VERSION ""

NS_ :

BS_:

BU_: VCU BMU TMS Fire

BO_ 2550330351 V2BCMD: 8 VCU
 SG_ V2BCMDLifeSignal : 0|8@1+ (1,0) [0|255] ""  BMU
 SG_ V2BCMDHVOnOff : 8|2@1+ (1,0) [0|3] ""  BMU
 SG_ V2BCMDAux1OnOff : 10|2@1+ (1,0) [0|3] ""  BMU
 SG_ V2BCMDAux2OnOff : 12|2@1+ (1,0) [0|3] ""  BMU
 SG_ V2BCMDAux3OnOff : 14|2@1+ (1,0) [0|3] ""  BMU
 SG_ V2BCMDVehicleSpeed : 16|8@1+ (1,0) [0|255] "km/h"  BMU
 SG_ V2BCMDBatteryContactorPosST : 24|2@1+ (1,0) [0|3] ""  BMU
 SG_ V2BCMDBatteryContactorPosFlt : 26|2@1+ (1,0) [0|3] ""  BMU
 SG_ V2BCMDBatteryContactorNegST : 28|2@1+ (1,0) [0|3] ""  BMU
 SG_ V2BCMDBatteryContactorNegFlt : 30|2@1+ (1,0) [0|3] ""  BMU
 SG_ V2BCMDDCChargeContactorPosST : 32|2@1+ (1,0) [0|3] ""  BMU
 SG_ V2BCMDDCChargeContactorPosFlt : 34|2@1+ (1,0) [0|3] ""  BMU
 SG_ V2BCMDDCChargeContactorNegST : 36|2@1+ (1,0) [0|3] ""  BMU
 SG_ V2BCMDDCChargeContactorNegFlt : 38|2@1+ (1,0) [0|3] ""  BMU
 SG_ V2BCMDPantographContactorPosST : 40|2@1+ (1,0) [0|3] ""  BMU
 SG_ V2BCMDPantographContactorPosFlt : 42|2@1+ (1,0) [0|3] ""  BMU
 SG_ V2BCMDPantographContactorNegST : 44|2@1+ (1,0) [0|3] ""  BMU
 SG_ V2BCMDPantographContactorNegFlt : 46|2@1+ (1,0) [0|3] ""  BMU
 SG_ V2BCMDCharge1RelayST : 48|2@1+ (1,0) [0|3] ""  BMU
 SG_ V2BCMDCharge1RelayFlt : 50|2@1+ (1,0) [0|3] ""  BMU
 SG_ V2BCMDCharge2RelayST : 52|2@1+ (1,0) [0|3] ""  BMU
 SG_ V2BCMDCharge2RelayFlt : 54|2@1+ (1,0) [0|3] ""  BMU
 SG_ V2BCMDAux4RelayST : 56|2@1+ (1,0) [0|3] ""  BMU
 SG_ V2BCMDAux4RelayFlt : 58|2@1+ (1,0) [0|3] ""  BMU
 SG_ V2BCMDReserved1 : 60|2@1+ (1,0) [0|3] ""  BMU
 SG_ V2BCMDReserved2 : 62|2@1+ (1,0) [0|3] ""  BMU

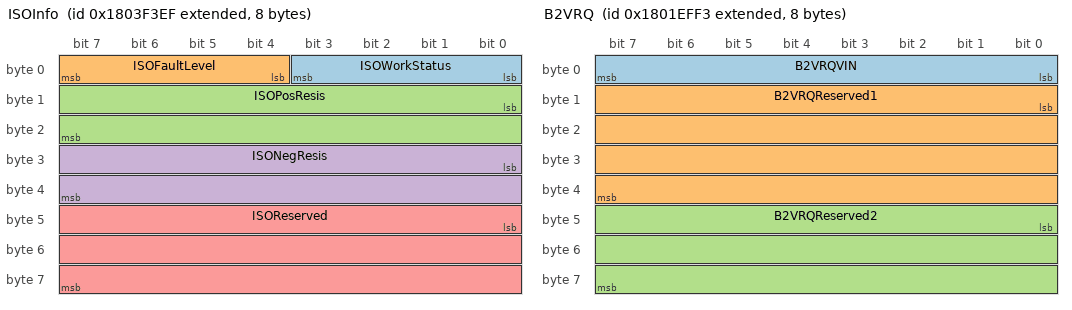
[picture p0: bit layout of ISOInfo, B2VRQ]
BO_ 2550395887 ISOInfo: 8 VCU
 SG_ ISOWorkStatus : 0|4@1+ (1,0) [0|15] ""  BMU
 SG_ ISOFaultLevel : 4|4@1+ (1,0) [0|15] ""  BMU
 SG_ ISOPosResis : 8|16@1+ (1,0) [0|60000] "kohm"  BMU
 SG_ ISONegResis : 24|16@1+ (1,0) [0|60000] "kohm"  BMU
 SG_ ISOReserved : 40|24@1+ (1,0) [0|16777215] ""  BMU

BO_ 2550263795 B2VRQ: 8 BMU
 SG_ B2VRQVIN : 0|8@1+ (1,0) [0|255] ""  VCU
 SG_ B2VRQReserved1 : 8|32@1+ (1,0) [0|4294967295] ""  VCU
 SG_ B2VRQReserved2 : 40|24@1+ (1,0) [0|16777215] ""  VCU

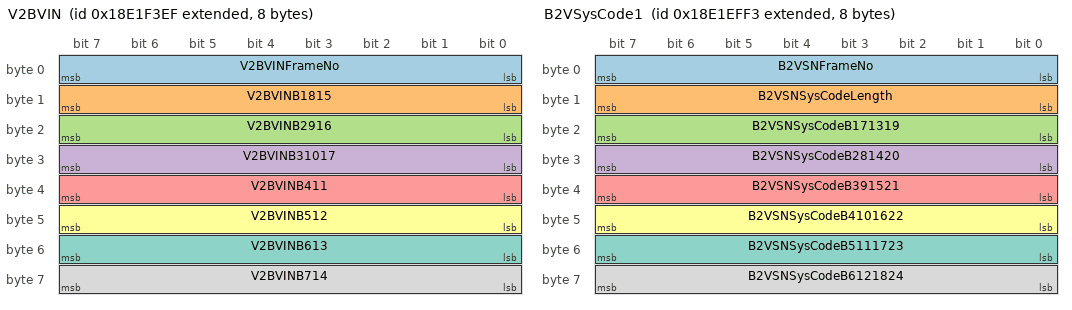
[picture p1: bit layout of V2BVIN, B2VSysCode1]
BO_ 2564944879 V2BVIN: 8 VCU
 SG_ V2BVINFrameNo : 0|8@1+ (1,0) [0|255] ""  BMU
 SG_ V2BVINB1815 : 8|8@1+ (1,0) [0|255] ""  BMU
 SG_ V2BVINB2916 : 16|8@1+ (1,0) [0|255] ""  BMU
 SG_ V2BVINB31017 : 24|8@1+ (1,0) [0|255] ""  BMU
 SG_ V2BVINB411 : 32|8@1+ (1,0) [0|255] ""  BMU
 SG_ V2BVINB512 : 40|8@1+ (1,0) [0|255] ""  BMU
 SG_ V2BVINB613 : 48|8@1+ (1,0) [0|255] ""  BMU
 SG_ V2BVINB714 : 56|8@1+ (1,0) [0|255] ""  BMU

BO_ 2564943859 B2VSysCode1: 8 BMU
 SG_ B2VSNFrameNo : 0|8@1+ (1,0) [0|255] ""  VCU
 SG_ B2VSNSysCodeLength : 8|8@1+ (1,0) [0|255] ""  VCU
 SG_ B2VSNSysCodeB171319 : 16|8@1+ (1,0) [0|255] ""  VCU
 SG_ B2VSNSysCodeB281420 : 24|8@1+ (1,0) [0|255] ""  VCU
 SG_ B2VSNSysCodeB391521 : 32|8@1+ (1,0) [0|255] ""  VCU
 SG_ B2VSNSysCodeB4101622 : 40|8@1+ (1,0) [0|255] ""  VCU
 SG_ B2VSNSysCodeB5111723 : 48|8@1+ (1,0) [0|255] ""  VCU
 SG_ B2VSNSysCodeB6121824 : 56|8@1+ (1,0) [0|255] ""  VCU

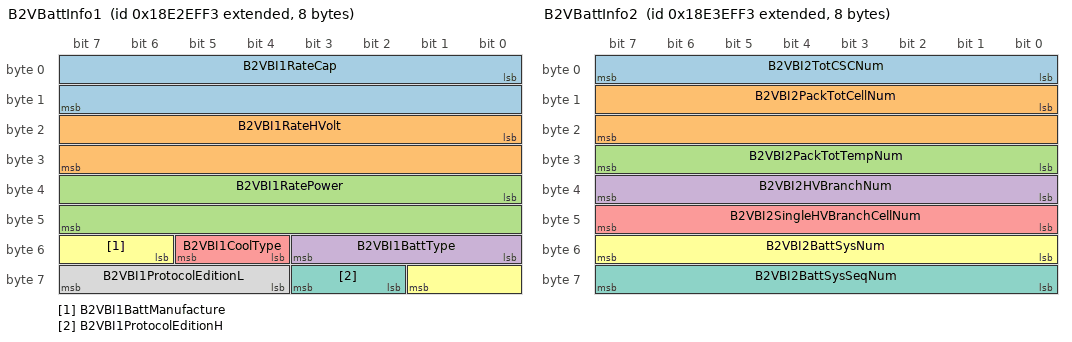
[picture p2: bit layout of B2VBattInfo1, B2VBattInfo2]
BO_ 2565009395 B2VBattInfo1: 8 BMU
 SG_ B2VBI1RateCap : 0|16@1+ (0.1,0) [0|6553.5] "Ah"  VCU
 SG_ B2VBI1RateHVolt : 16|16@1+ (0.1,0) [0|6553.5] "V"  VCU
 SG_ B2VBI1RatePower : 32|16@1+ (0.1,0) [0|6553.5] "kWh"  VCU
 SG_ B2VBI1BattType : 48|4@1+ (1,0) [0|15] ""  VCU
 SG_ B2VBI1CoolType : 52|2@1+ (1,0) [0|3] ""  VCU
 SG_ B2VBI1BattManufacture : 54|4@1+ (1,0) [0|15] ""  VCU
 SG_ B2VBI1ProtocolEditionH : 58|2@1+ (1,0) [0|3] ""  VCU
 SG_ B2VBI1ProtocolEditionL : 60|4@1+ (1,0) [0|15] ""  VCU

BO_ 2565074931 B2VBattInfo2: 8 BMU
 SG_ B2VBI2TotCSCNum : 0|8@1+ (1,0) [0|255] ""  VCU
 SG_ B2VBI2PackTotCellNum : 8|16@1+ (1,0) [0|65535] ""  VCU
 SG_ B2VBI2PackTotTempNum : 24|8@1+ (1,0) [0|255] ""  VCU
 SG_ B2VBI2HVBranchNum : 32|8@1+ (1,0) [0|5] ""  VCU
 SG_ B2VBI2SingleHVBranchCellNum : 40|8@1+ (1,0) [0|5] ""  VCU
 SG_ B2VBI2BattSysNum : 48|8@1+ (1,0) [0|5] ""  VCU
 SG_ B2VBI2BattSysSeqNum : 56|8@1+ (1,0) [0|5] ""  VCU

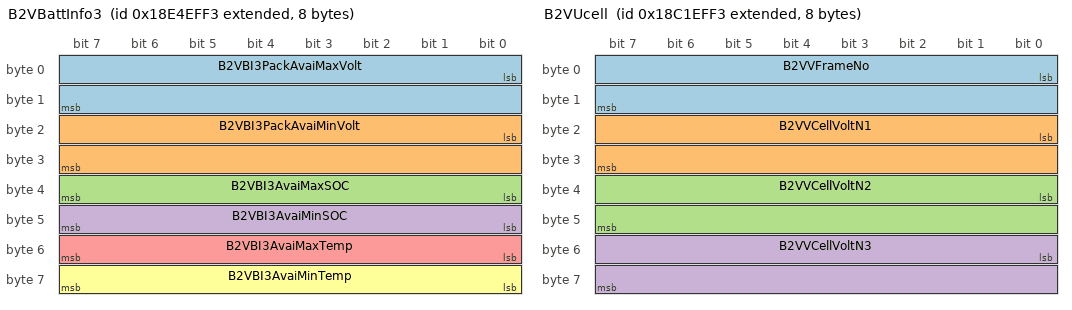
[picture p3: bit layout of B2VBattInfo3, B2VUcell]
BO_ 2565140467 B2VBattInfo3: 8 BMU
 SG_ B2VBI3PackAvaiMaxVolt : 0|16@1+ (0.1,0) [0|6553.5] "V"  VCU
 SG_ B2VBI3PackAvaiMinVolt : 16|16@1+ (0.1,0) [0|6553.5] "V"  VCU
 SG_ B2VBI3AvaiMaxSOC : 32|8@1+ (0.4,0) [0|102] "%"  VCU
 SG_ B2VBI3AvaiMinSOC : 40|8@1+ (0.4,0) [0|102] "%"  VCU
 SG_ B2VBI3AvaiMaxTemp : 48|8@1+ (1,-40) [-40|215] "℃"  VCU
 SG_ B2VBI3AvaiMinTemp : 56|8@1+ (1,-40) [-40|215] "℃"  VCU

BO_ 2562846707 B2VUcell: 8 BMU
 SG_ B2VVFrameNo : 0|16@1+ (1,0) [0|65535] ""  VCU
 SG_ B2VVCellVoltN1 : 16|16@1+ (0.001,0) [0|65.535] "V"  VCU
 SG_ B2VVCellVoltN2 : 32|16@1+ (0.001,0) [0|65.535] "V"  VCU
 SG_ B2VVCellVoltN3 : 48|16@1+ (0.001,0) [0|65.535] "V"  VCU

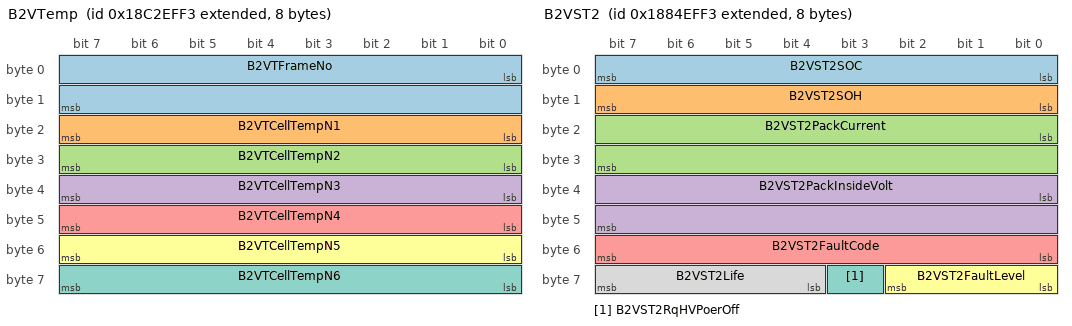
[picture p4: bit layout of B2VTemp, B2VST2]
BO_ 2562912243 B2VTemp: 8 BMU
 SG_ B2VTFrameNo : 0|16@1+ (1,0) [0|65535] ""  VCU
 SG_ B2VTCellTempN1 : 16|8@1+ (1,-40) [-40|215] "℃"  VCU
 SG_ B2VTCellTempN2 : 24|8@1+ (1,-40) [-40|215] "℃"  VCU
 SG_ B2VTCellTempN3 : 32|8@1+ (1,-40) [-40|215] "℃"  VCU
 SG_ B2VTCellTempN4 : 40|8@1+ (1,-40) [-40|215] "℃"  VCU
 SG_ B2VTCellTempN5 : 48|8@1+ (1,-40) [-40|215] "℃"  VCU
 SG_ B2VTCellTempN6 : 56|8@1+ (1,-40) [-40|215] "℃"  VCU

BO_ 2558652403 B2VFult132960: 8 BMU
 SG_ B2VFult132960Reserved1 : 0|2@1+ (1,0) [0|3] ""  VCU
 SG_ B2VFult1DelTemp : 2|2@1+ (1,0) [0|3] ""  VCU
 SG_ B2VFult1OverTemp : 4|2@1+ (1,0) [0|3] ""  VCU
 SG_ B2VFult1PackOverHVolt : 6|2@1+ (1,0) [0|3] ""  VCU
 SG_ B2VFult1PackLowHVolt : 8|2@1+ (1,0) [0|3] ""  VCU
 SG_ B2VFult1LowSOC : 10|2@1+ (1,0) [0|3] ""  VCU
 SG_ B2VFult1OverUcell : 12|2@1+ (1,0) [0|3] ""  VCU
 SG_ B2VFult1LowUcell : 14|2@1+ (1,0) [0|3] ""  VCU
 SG_ B2VFult1LowInsRes : 16|2@1+ (1,0) [0|3] ""  VCU
 SG_ B2VFult1UcellUniformity : 18|2@1+ (1,0) [0|3] ""  VCU
 SG_ B2VFult1OverChg : 20|2@1+ (1,0) [0|3] ""  VCU
 SG_ B2VFult1OverSOC : 22|2@1+ (1,0) [0|3] ""  VCU
 SG_ B2VFult1SOCChangeFast : 24|1@1+ (1,0) [0|1] ""  VCU
 SG_ B2VFult1BatSysNotMatch : 25|1@1+ (1,0) [0|1] ""  VCU
 SG_ B2VFult1HVILFault : 26|1@1+ (1,0) [0|1] ""  VCU
 SG_ B2VFult1FaultNum32960 : 27|5@1+ (1,0) [0|31] ""  VCU
 SG_ B2VFult132960Reserved2 : 32|32@1+ (1,0) [0|4294967295] ""  VCU

BO_ 2558717939 B2VFult2: 8 BMU
 SG_ B2VFult2FaultNum : 0|8@1+ (1,0) [0|255] ""  VCU
 SG_ B2VFult2CellOverDischrg : 8|1@1+ (1,0) [0|1] ""  VCU
 SG_ B2VFult2CellLowTemp : 9|1@1+ (1,0) [0|1] ""  VCU
 SG_ B2VFult2PackFireWarning : 10|1@1+ (1,0) [0|1] ""  VCU
 SG_ B2VFult2OverDischrgCurr : 11|2@1+ (1,0) [0|3] ""  VCU
 SG_ B2VFult2OverChrgCurrInTheDrive : 13|2@1+ (1,0) [0|3] ""  VCU
 SG_ B2VFult2CurrSensorErr : 15|1@1+ (1,0) [0|1] ""  VCU
 SG_ B2VFult2PowerSupplyErr : 16|1@1+ (1,0) [0|1] ""  VCU
 SG_ B2VFult2TMSErr : 17|1@1+ (1,0) [0|1] ""  VCU
 SG_ B2VFult2HeatungFilmErr : 18|1@1+ (1,0) [0|1] ""  VCU
 SG_ B2VFult2PackSelfProtect : 19|1@1+ (1,0) [0|1] ""  VCU
 SG_ B2VFult2MainLoopPrechrgErr : 20|1@1+ (1,0) [0|1] ""  VCU
 SG_ B2VFult2AuxLoopPrechrgErr : 21|1@1+ (1,0) [0|1] ""  VCU
 SG_ B2VFult2ChrgInsLowErr : 22|1@1+ (1,0) [0|1] ""  VCU
 SG_ B2VFult2ACANLost : 23|1@1+ (1,0) [0|1] ""  VCU
 SG_ B2VFult2InnerCommunicationErr : 24|1@1+ (1,0) [0|1] ""  VCU
 SG_ B2VFult2DCDCErr : 25|1@1+ (1,0) [0|1] ""  VCU
 SG_ B2VFult2BranchBreakErr : 26|1@1+ (1,0) [0|1] ""  VCU
 SG_ B2VFult2HeatRelayOpenErr : 27|1@1+ (1,0) [0|1] ""  VCU
 SG_ B2VFult2HeatRelayWeldErr : 28|1@1+ (1,0) [0|1] ""  VCU
 SG_ B2VFult2MainPosRelayOpenErr : 29|1@1+ (1,0) [0|1] ""  VCU
 SG_ B2VFult2MainPosRelayWeldErr : 30|1@1+ (1,0) [0|1] ""  VCU
 SG_ B2VFult2MainNegRelayOpenErr : 31|1@1+ (1,0) [0|1] ""  VCU
 SG_ B2VFult2MainNegRelayWeldErr : 32|1@1+ (1,0) [0|1] ""  VCU
 SG_ B2VFult2DCChrgPos1RelayOpenErr : 33|1@1+ (1,0) [0|1] ""  VCU
 SG_ B2VFult2DCChrgPos1RelayWeldErr : 34|1@1+ (1,0) [0|1] ""  VCU
 SG_ B2VFult2DCChrgNeg1RelayOpenErr : 35|1@1+ (1,0) [0|1] ""  VCU
 SG_ B2VFult2DCChrgNeg1RelayWeldErr : 36|1@1+ (1,0) [0|1] ""  VCU
 SG_ B2VFult2DCChrgPos2RelayOpenErr : 37|1@1+ (1,0) [0|1] ""  VCU
 SG_ B2VFult2DCChrgPos2RelayWeldErr : 38|1@1+ (1,0) [0|1] ""  VCU
 SG_ B2VFult2DCChrgNeg2RelayOpenErr : 39|1@1+ (1,0) [0|1] ""  VCU
 SG_ B2VFult2DCChrgNeg2RelayWeldErr : 40|1@1+ (1,0) [0|1] ""  VCU
 SG_ B2VFult2ACChrgPosRelayOpenErr : 41|1@1+ (1,0) [0|1] ""  VCU
 SG_ B2VFult2ACChrgPosRelayWeldErr : 42|1@1+ (1,0) [0|1] ""  VCU
 SG_ B2VFult2ACChrgNegRelayOpenErr : 43|1@1+ (1,0) [0|1] ""  VCU
 SG_ B2VFult2ACChrgNegRelayWeldErr : 44|1@1+ (1,0) [0|1] ""  VCU
 SG_ B2VFult2PantoChrgPosRelayOpenErr : 45|1@1+ (1,0) [0|1] ""  VCU
 SG_ B2VFult2PantoChrgPosRelayWeldErr : 46|1@1+ (1,0) [0|1] ""  VCU
 SG_ B2VFult2PantoChrgNegRelayOpenErr : 47|1@1+ (1,0) [0|1] ""  VCU
 SG_ B2VFult2PantoChrgNegRelayWeldErr : 48|1@1+ (1,0) [0|1] ""  VCU
 SG_ B2VFult2ChrgConnectErr : 49|1@1+ (1,0) [0|1] ""  VCU
 SG_ B2VFlt2OverDschrgCrrWhnInChrg : 50|1@1+ (1,0) [0|1] ""  VCU
 SG_ B2VFult2OverChrgCurrInTheChrg : 51|1@1+ (1,0) [0|1] ""  VCU
 SG_ B2VFult2ChrgNTCErr : 52|1@1+ (1,0) [0|1] ""  VCU
 SG_ B2VFult2ChrgNTCTempOver : 53|2@1+ (1,0) [0|3] ""  VCU
 SG_ B2VFult2ELockErr : 55|1@1+ (1,0) [0|1] ""  VCU
 SG_ B2VFult2FireDetectorErr : 56|1@1+ (1,0) [0|1] ""  VCU
 SG_ B2VFult2ContiChrgCurrOverLoad : 57|2@1+ (1,0) [0|3] ""  VCU
 SG_ B2VFult2SOCDifferErr : 59|1@1+ (1,0) [0|1] ""  VCU
 SG_ B2VFult2ContiDischrgCurrOverLoad : 60|2@1+ (1,0) [0|3] ""  VCU
 SG_ B2VFult2Reserved1 : 62|1@1+ (1,0) [0|1] ""  VCU
 SG_ B2VFult2Reserved2 : 63|1@1+ (1,0) [0|1] ""  VCU

BO_ 2558783475 B2VST1: 8 BMU
 SG_ B2VST1MainPosRelaySt : 0|2@1+ (1,0) [0|3] ""  VCU
 SG_ B2VST1MainNegRelaySt : 2|2@1+ (1,0) [0|3] ""  VCU
 SG_ B2VST1PrechrgRelaySt : 4|2@1+ (1,0) [0|3] ""  VCU
 SG_ B2VST1DCChrgPos1RelaySt : 6|2@1+ (1,0) [0|3] ""  VCU
 SG_ B2VST1DCChrgNeg1RelaySt : 8|2@1+ (1,0) [0|3] ""  VCU
 SG_ B2VST1DCChrgPos2RelaySt : 10|2@1+ (1,0) [0|3] ""  VCU
 SG_ B2VST1DCChrgNeg2RelaySt : 12|2@1+ (1,0) [0|3] ""  VCU
 SG_ B2VST1HeatPosRelaySt : 14|2@1+ (1,0) [0|3] ""  VCU
 SG_ B2VST1HeatNegRelaySt : 16|2@1+ (1,0) [0|3] ""  VCU
 SG_ B2VST1PantoChrgPosRelaySt : 18|2@1+ (1,0) [0|3] ""  VCU
 SG_ B2VST1PantoChrgNegRelaySt : 20|2@1+ (1,0) [0|3] ""  VCU
 SG_ B2VST1ACChrgPosRelaySt : 22|2@1+ (1,0) [0|3] ""  VCU
 SG_ B2VST1ACChrgNegRelaySt : 24|2@1+ (1,0) [0|3] ""  VCU
 SG_ B2VST1Aux1RelaySt : 26|2@1+ (1,0) [0|3] ""  VCU
 SG_ B2VST1Aux2RelaySt : 28|2@1+ (1,0) [0|3] ""  VCU
 SG_ B2VST1Aux3RelaySt : 30|2@1+ (1,0) [0|3] ""  VCU
 SG_ B2VST1BMSHVStatus : 32|2@1+ (1,0) [0|3] ""  VCU
 SG_ B2VST1BMSBalanceStatus : 34|1@1+ (1,0) [0|1] ""  VCU
 SG_ B2VST1DCChrgConnectSt : 35|2@1+ (1,0) [0|3] ""  VCU
 SG_ B2VST1PantoChrgConnectSt : 37|1@1+ (1,0) [0|1] ""  VCU
 SG_ B2VST1ACChrgConnectSt : 38|1@1+ (1,0) [0|1] ""  VCU
 SG_ B2VST1ChrgMode : 39|2@1+ (1,0) [0|3] ""  VCU
 SG_ B2VST1ChrgStatus : 41|2@1+ (1,0) [0|3] ""  VCU
 SG_ B2VST1HeatingStatus : 43|1@1+ (1,0) [0|1] ""  VCU
 SG_ B2VST1CoolingStatus : 44|2@1+ (1,0) [0|3] ""  VCU
 SG_ B2VST1RechrgCycels : 46|18@1+ (1,0) [0|262143] ""  VCU

BO_ 2558849011 B2VST2: 8 BMU
 SG_ B2VST2SOC : 0|8@1+ (0.4,0) [0|100] "%"  VCU
 SG_ B2VST2SOH : 8|8@1+ (0.4,0) [0|100] "%"  VCU
 SG_ B2VST2PackCurrent : 16|16@1+ (0.1,-1000) [-1000|1000] "A"  VCU
 SG_ B2VST2PackInsideVolt : 32|16@1+ (0.1,0) [0|65535] "V"  VCU
 SG_ B2VST2FaultCode : 48|8@1+ (1,0) [0|255] ""  VCU
 SG_ B2VST2FaultLevel : 56|3@1+ (1,0) [0|7] ""  VCU
 SG_ B2VST2RqHVPoerOff : 59|1@1+ (1,0) [0|1] ""  VCU
 SG_ B2VST2Life : 60|4@1+ (1,0) [0|15] ""  VCU

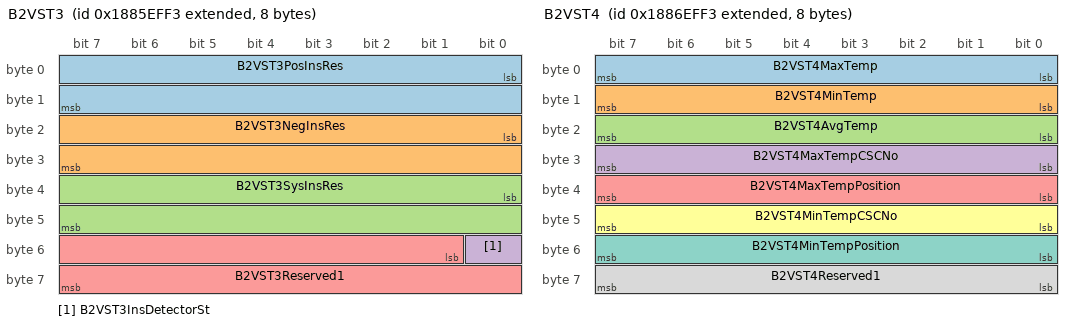
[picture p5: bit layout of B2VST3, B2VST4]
BO_ 2558914547 B2VST3: 8 BMU
 SG_ B2VST3PosInsRes : 0|16@1+ (1,0) [0|60000] "kohm"  VCU
 SG_ B2VST3NegInsRes : 16|16@1+ (1,0) [0|60000] "kohm"  VCU
 SG_ B2VST3SysInsRes : 32|16@1+ (1,0) [0|60000] "kohm"  VCU
 SG_ B2VST3InsDetectorSt : 48|1@1+ (1,0) [0|1] ""  VCU
 SG_ B2VST3Reserved1 : 49|15@1+ (1,0) [0|32767] ""  VCU

BO_ 2558980083 B2VST4: 8 BMU
 SG_ B2VST4MaxTemp : 0|8@1+ (1,-40) [-40|215] "℃"  VCU
 SG_ B2VST4MinTemp : 8|8@1+ (1,-40) [-40|215] "℃"  VCU
 SG_ B2VST4AvgTemp : 16|8@1+ (1,-40) [-40|215] "℃"  VCU
 SG_ B2VST4MaxTempCSCNo : 24|8@1+ (1,0) [1|255] ""  VCU
 SG_ B2VST4MaxTempPosition : 32|8@1+ (1,0) [1|255] ""  VCU
 SG_ B2VST4MinTempCSCNo : 40|8@1+ (1,0) [1|255] ""  VCU
 SG_ B2VST4MinTempPosition : 48|8@1+ (1,0) [1|255] ""  VCU
 SG_ B2VST4Reserved1 : 56|8@1+ (1,0) [1|255] ""  VCU

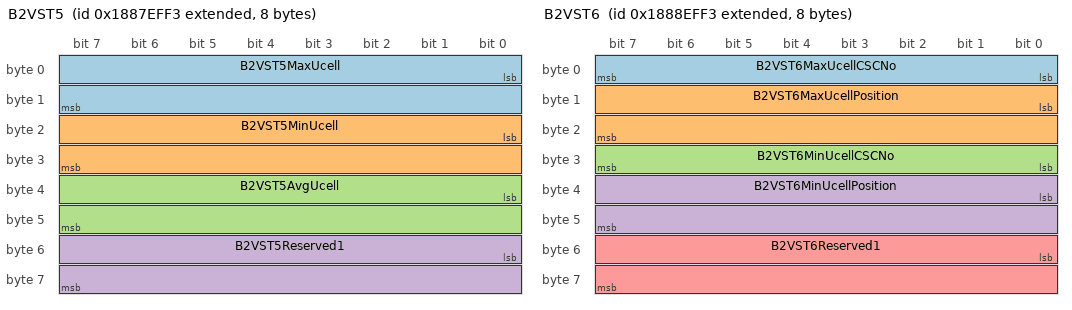
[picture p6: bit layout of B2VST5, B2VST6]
BO_ 2559045619 B2VST5: 8 BMU
 SG_ B2VST5MaxUcell : 0|16@1+ (0.001,0) [0|65.535] "V"  VCU
 SG_ B2VST5MinUcell : 16|16@1+ (0.001,0) [0|65.535] "V"  VCU
 SG_ B2VST5AvgUcell : 32|16@1+ (0.001,0) [0|65.535] "V"  VCU
 SG_ B2VST5Reserved1 : 48|16@1+ (1,0) [0|65535] ""  VCU

BO_ 2559111155 B2VST6: 8 BMU
 SG_ B2VST6MaxUcellCSCNo : 0|8@1+ (1,0) [0|255] ""  VCU
 SG_ B2VST6MaxUcellPosition : 8|16@1+ (1,0) [0|65535] ""  VCU
 SG_ B2VST6MinUcellCSCNo : 24|8@1+ (1,0) [0|255] ""  VCU
 SG_ B2VST6MinUcellPosition : 32|16@1+ (1,0) [0|65535] ""  VCU
 SG_ B2VST6Reserved1 : 48|16@1+ (1,0) [0|65535] ""  VCU

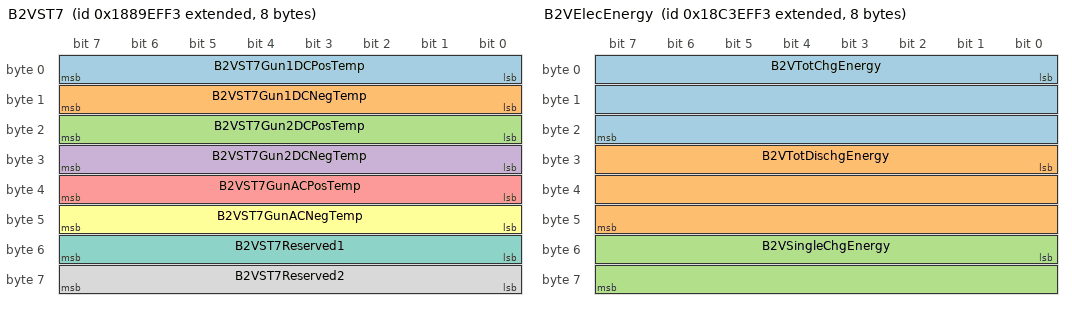
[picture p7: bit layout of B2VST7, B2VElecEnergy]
BO_ 2559176691 B2VST7: 8 BMU
 SG_ B2VST7Gun1DCPosTemp : 0|8@1+ (1,-40) [-40|215] "℃"  VCU
 SG_ B2VST7Gun1DCNegTemp : 8|8@1+ (1,-40) [-40|215] "℃"  VCU
 SG_ B2VST7Gun2DCPosTemp : 16|8@1+ (1,-40) [-40|215] "℃"  VCU
 SG_ B2VST7Gun2DCNegTemp : 24|8@1+ (1,-40) [-40|215] "℃"  VCU
 SG_ B2VST7GunACPosTemp : 32|8@1+ (1,-40) [-40|215] "℃"  VCU
 SG_ B2VST7GunACNegTemp : 40|8@1+ (1,-40) [-40|215] "℃"  VCU
 SG_ B2VST7Reserved1 : 48|8@1+ (1,0) [0|255] ""  VCU
 SG_ B2VST7Reserved2 : 56|8@1+ (1,0) [0|255] ""  VCU

BO_ 2562977779 B2VElecEnergy: 8 BMU
 SG_ B2VTotChgEnergy : 0|24@1+ (1,0) [0|16777215] "kwh"  VCU
 SG_ B2VTotDischgEnergy : 24|24@1+ (1,0) [0|16777215] "kwh"  VCU
 SG_ B2VSingleChgEnergy : 48|16@1+ (0.1,0) [0|6553.5] "kwh"  VCU

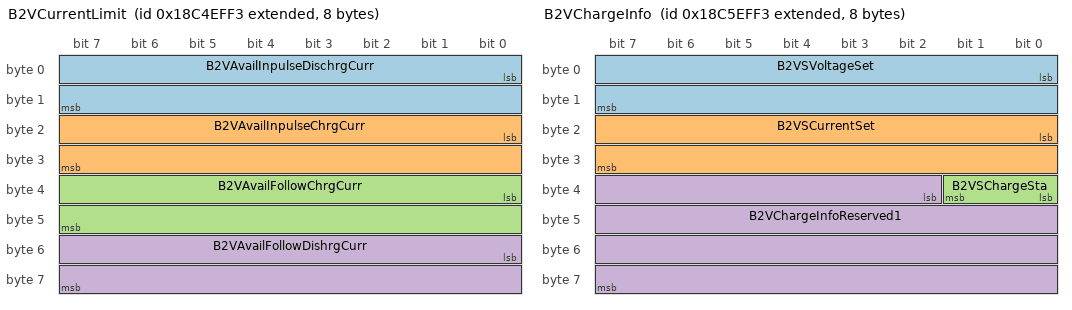
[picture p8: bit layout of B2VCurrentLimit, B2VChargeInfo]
BO_ 2563043315 B2VCurrentLimit: 8 BMU
 SG_ B2VAvailInpulseDischrgCurr : 0|16@1+ (0.1,0) [0|6553.5] "A"  VCU
 SG_ B2VAvailInpulseChrgCurr : 16|16@1+ (0.1,0) [0|6553.5] "A"  VCU
 SG_ B2VAvailFollowChrgCurr : 32|16@1+ (0.1,0) [0|6553.5] "A"  VCU
 SG_ B2VAvailFollowDishrgCurr : 48|16@1+ (0.1,0) [0|6553.5] "A"  VCU

BO_ 2563108851 B2VChargeInfo: 8 BMU
 SG_ B2VSVoltageSet : 0|16@1+ (0.1,0) [0|6553.5] "V"  VCU
 SG_ B2VSCurrentSet : 16|16@1+ (0.1,0) [0|6553.5] "A"  VCU
 SG_ B2VSChargeSta : 32|2@1+ (1,0) [0|3] ""  VCU
 SG_ B2VChargeInfoReserved1 : 34|30@1+ (1,0) [0|1073741823] ""  VCU

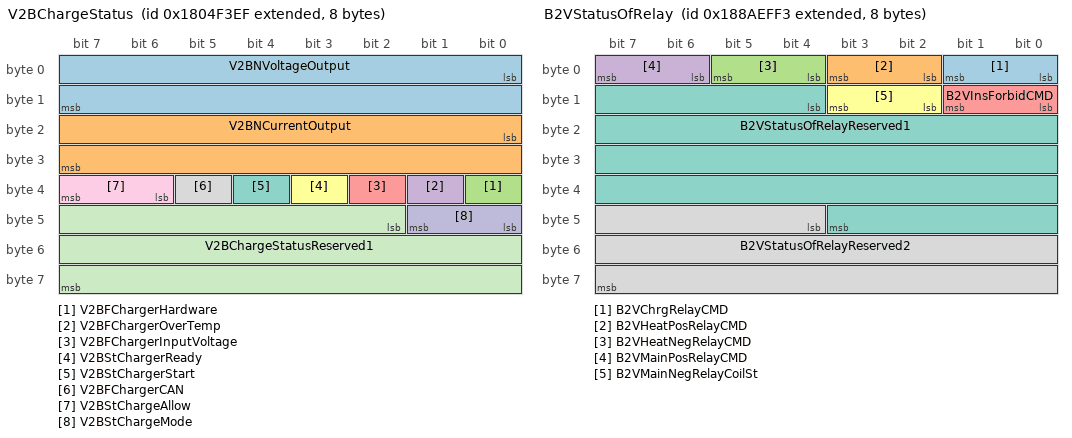
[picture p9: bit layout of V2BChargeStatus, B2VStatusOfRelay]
BO_ 2550461423 V2BChargeStatus: 8 VCU
 SG_ V2BNVoltageOutput : 0|16@1+ (0.1,0) [0|6553.5] "V"  BMU
 SG_ V2BNCurrentOutput : 16|16@1+ (0.1,0) [0|6553.5] "A"  BMU
 SG_ V2BFChargerHardware : 32|1@1+ (1,0) [0|1] ""  BMU
 SG_ V2BFChargerOverTemp : 33|1@1+ (1,0) [0|1] ""  BMU
 SG_ V2BFChargerInputVoltage : 34|1@1+ (1,0) [0|1] ""  BMU
 SG_ V2BStChargerReady : 35|1@1+ (1,0) [0|1] ""  BMU
 SG_ V2BStChargerStart : 36|1@1+ (1,0) [0|1] ""  BMU
 SG_ V2BFChargerCAN : 37|1@1+ (1,0) [0|1] ""  BMU
 SG_ V2BStChargeAllow : 38|2@1+ (1,0) [0|3] ""  BMU
 SG_ V2BStChargeMode : 40|2@1+ (1,0) [0|3] ""  BMU
 SG_ V2BChargeStatusReserved1 : 42|22@1+ (1,0) [0|8388607] ""  BMU

BO_ 2559242227 B2VStatusOfRelay: 8 BMU
 SG_ B2VChrgRelayCMD : 0|2@1+ (1,0) [0|3] ""  VCU
 SG_ B2VHeatPosRelayCMD : 2|2@1+ (1,0) [0|3] ""  VCU
 SG_ B2VHeatNegRelayCMD : 4|2@1+ (1,0) [0|3] ""  VCU
 SG_ B2VMainPosRelayCMD : 6|2@1+ (1,0) [0|3] ""  VCU
 SG_ B2VInsForbidCMD : 8|2@1+ (1,0) [0|3] ""  VCU
 SG_ B2VMainNegRelayCoilSt : 10|2@1+ (1,0) [0|3] ""  VCU
 SG_ B2VStatusOfRelayReserved1 : 12|32@1+ (1,0) [0|4294967295] ""  VCU
 SG_ B2VStatusOfRelayReserved2 : 44|20@1+ (1,0) [0|1048575] ""  VCU

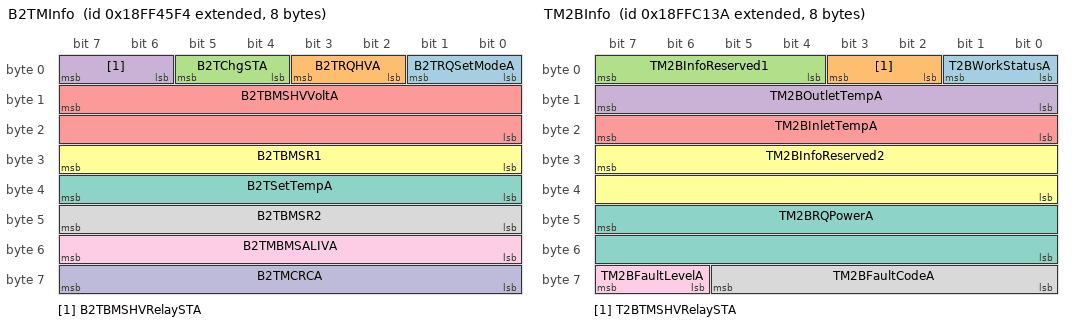
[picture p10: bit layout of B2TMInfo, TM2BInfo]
BO_ 2566866420 B2TMInfo: 8 BMU
 SG_ B2TRQSetModeA : 1|2@0+ (1,0) [0|3] ""  TMS
 SG_ B2TRQHVA : 3|2@0+ (1,0) [0|3] ""  TMS
 SG_ B2TChgSTA : 5|2@0+ (1,0) [0|3] ""  TMS
 SG_ B2TBMSHVRelaySTA : 7|2@0+ (1,0) [0|3] ""  TMS
 SG_ B2TBMSHVVoltA : 15|16@0+ (1,0) [0|65535] ""  TMS
 SG_ B2TBMSR1 : 31|8@0+ (1,0) [0|255] ""  TMS
 SG_ B2TSetTempA : 39|8@0+ (1,-40) [-40|215] "℃"  TMS
 SG_ B2TBMSR2 : 47|8@0+ (1,0) [0|255] ""  TMS
 SG_ B2TMBMSALIVA : 55|8@0+ (1,0) [0|255] ""  TMS
 SG_ B2TMCRCA : 63|8@0+ (1,0) [0|255] ""  TMS

BO_ 2566897978 TM2BInfo: 8 TMS
 SG_ T2BWorkStatusA : 1|2@0+ (1,0) [0|3] ""  BMU
 SG_ T2BTMSHVRelaySTA : 3|2@0+ (1,0) [0|3] ""  BMU
 SG_ TM2BInfoReserved1 : 7|4@0+ (1,0) [0|15] ""  BMU
 SG_ TM2BOutletTempA : 15|8@0+ (1,-40) [-40|215] "℃"  BMU
 SG_ TM2BInletTempA : 23|8@0+ (1,-40) [-40|215] "℃"  BMU
 SG_ TM2BInfoReserved2 : 31|16@0+ (1,0) [0|65535] ""  BMU
 SG_ TM2BRQPowerA : 47|16@0+ (0.1,0) [0|6553.5] "Kw"  BMU
 SG_ TM2BFaultCodeA : 61|6@0+ (1,0) [0|63] ""  BMU
 SG_ TM2BFaultLevelA : 63|2@0+ (1,0) [0|3] ""  BMU

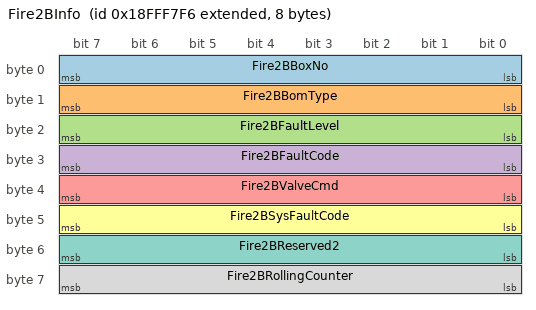
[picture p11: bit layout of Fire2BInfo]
BO_ 2566911990 Fire2BInfo: 8 Fire
 SG_ Fire2BBoxNo : 0|8@1+ (1,0) [0|255] ""  BMU
 SG_ Fire2BBomType : 8|8@1+ (1,0) [0|255] ""  BMU
 SG_ Fire2BFaultLevel : 16|8@1+ (1,0) [0|255] ""  BMU
 SG_ Fire2BFaultCode : 24|8@1+ (1,0) [0|255] ""  BMU
 SG_ Fire2BValveCmd : 32|8@1+ (1,0) [0|255] ""  BMU
 SG_ Fire2BSysFaultCode : 40|8@1+ (1,0) [0|255] ""  BMU
 SG_ Fire2BReserved2 : 48|8@1+ (1,0) [0|255] ""  BMU
 SG_ Fire2BRollingCounter : 56|8@1+ (1,0) [0|255] ""  BMU

CM_ BO_ 2550330351 "VCU发送到BMS的命令
The command message from VCU to BMS";
CM_ SG_ 2550330351 V2BCMDLifeSignal "VCU生命信号
Life signal of VCU";
CM_ SG_ 2550330351 V2BCMDHVOnOff "整车发给BMS的主回路上下高压指令
High voltage power on/off command from VCU to BMS";
CM_ SG_ 2550330351 V2BCMDAux1OnOff "整车发给BMS的附件1回路上下高压指令（无该附件回路则发0x00）
Command of high voltage to auxiliary_1 contactor(filled in 0 if BMS have no auxiliary_1 contactor)";
CM_ SG_ 2550330351 V2BCMDAux2OnOff "整车发给BMS的附件2回路上下高压指令（无该附件回路则发0x00）
Command of high voltage to auxiliary_2 contactor(filled in 0 if BMS have no auxiliary_2 contactor)";
CM_ SG_ 2550330351 V2BCMDAux3OnOff "整车发给BMS的附件3回路上下高压指令（无该附件回路则发0x00）
Command of high voltage to auxiliary_3 contactor
(filled in 0 if BMS have no auxiliary_3 contactor)";
CM_ SG_ 2550330351 V2BCMDVehicleSpeed "车速
Vehicle Speed";
CM_ SG_ 2550330351 V2BCMDBatteryContactorPosST "整车端电池正继电器触点状态（无该继电器则发0x00）
Status of vehicle Battery Contactor-positive (filled in 0 if vehicle have no this contactor)";
CM_ SG_ 2550330351 V2BCMDBatteryContactorPosFlt "整车端电池正继电器故障状态（无该继电器则发0x00）
Fault of vehicle Battery Contactor-positive  (filled in 0 if vehicle have no this contactor)";
CM_ SG_ 2550330351 V2BCMDBatteryContactorNegST "整车端电池负继电器触点状态（无该继电器则发0x00）
Status of vehicle Battery Contactor-negative (filled in 0 if vehicle have no vehicle Battery Contactor-negative)";
CM_ SG_ 2550330351 V2BCMDBatteryContactorNegFlt "整车端电池负继电器故障状态（无该继电器则发0x00）
Fault of vehicle Battery Contactor-negative (filled in 0 if vehicle have no vehicle Battery Contactor-negative)";
CM_ SG_ 2550330351 V2BCMDDCChargeContactorPosST "整车端DC Charge Contactor正触点状态（无该继电器则发0x00）
Status of vehicle DC Charge Contactor positive (filled in 0 if vehicle have no this contactor)";
CM_ SG_ 2550330351 V2BCMDDCChargeContactorPosFlt "整车端DC Charge Contactor正故障状态（无该继电器则发0x00）
Fault of vehicle DC Charge Contactor positive (filled in 0 if vehicle have no this contactor)";
CM_ SG_ 2550330351 V2BCMDDCChargeContactorNegST "整车端DC Charge Contactor负触点状态（无该继电器则发0x00）
Status of vehicle DC Charge Contactor negative (filled in 0 if vehicle have no this contactor)";
CM_ SG_ 2550330351 V2BCMDDCChargeContactorNegFlt "整车端DC Charge Contactor负故障状态（无该继电器则发0x00）
Fault of vehicle DC Charge Contactor negative (filled in 0 if vehicle have no this contactor)";
CM_ SG_ 2550330351 V2BCMDPantographContactorPosST "整车端Pantograph Contactor正触点状态（无该继电器则发0x00）
Status of vehicle Pantograph Contactor positive (filled in 0 if vehicle have no this contactor)";
CM_ SG_ 2550330351 V2BCMDPantographContactorPosFlt "整车端Pantograph Contactor正故障状态（无该继电器则发0x00）
Fault of vehicle Pantograph Contactor positive (filled in 0 if vehicle have no this contactor)";
CM_ SG_ 2550330351 V2BCMDPantographContactorNegST "整车端Pantograph Contactor负触点状态（无该继电器则发0x00）
Status of vehicle Pantograph Contactor negative (filled in 0 if vehicle have no this contactor)";
CM_ SG_ 2550330351 V2BCMDPantographContactorNegFlt "整车端Pantograph Contactor负故障状态（无该继电器则发0x00）
Fault of vehicle Pantograph Contactor negative (filled in 0 if vehicle have no this contactor)";
CM_ SG_ 2550330351 V2BCMDCharge1RelayST "整车端Charge1 Contactor正触点状态（无该继电器则发0x00）
Status of vehicle Charge1 Contactor positive (filled in 0 if vehicle have no this contactor)";
CM_ SG_ 2550330351 V2BCMDCharge1RelayFlt "整车端Charge1 Contactor正故障状态（无该继电器则发0x00）
Fault of vehicle Charge1 Contactor positive (filled in 0 if vehicle have no this contactor)";
CM_ SG_ 2550330351 V2BCMDCharge2RelayST "整车端Charge2 Contactor正触点状态（无该继电器则发0x00）
Status of vehicle Charge2 Contactor positive (filled in 0 if vehicle have no this contactor)";
CM_ SG_ 2550330351 V2BCMDCharge2RelayFlt "整车端Charge2 Contactor正故障状态（无该继电器则发0x00）
Fault of vehicle Charge2 Contactor positive (filled in 0 if vehicle have no this contactor)";
CM_ SG_ 2550330351 V2BCMDAux4RelayST "整车端辅件4接触器触点状态（无该继电器则发0x00）
Status of vehicle auxiliary_4 contactor(filled in 0 if vehicle have no auxiliary_4 contactor)";
CM_ SG_ 2550330351 V2BCMDAux4RelayFlt "整车端辅件4接触器故障状态（无该继电器则发0x00）
Fault of vehicle auxiliary_4 contactor(filled in 0 if vehicle have no auxiliary_4 contactor)";
CM_ SG_ 2550330351 V2BCMDReserved1 "预留1(填充0)
Reserved-1(filled in 0)";
CM_ SG_ 2550330351 V2BCMDReserved2 "预留2(填充0)
Reserved-2(filled in 0)";
CM_ BO_ 2550395887 "整车采集的绝缘值（多合一项目或者整车采绝缘的项目）
vehicle insulation information(Project that vehicle have insulation montoring )";
CM_ SG_ 2550395887 ISOWorkStatus "绝缘检测仪工作状态（多合一项目或者整车采绝缘的项目）
Insulation detection status(Project that vehicle have insulation montoring )";
CM_ SG_ 2550395887 ISOFaultLevel "绝缘故障等级（多合一项目或者整车采绝缘的项目）
Fault level of insulation detection(Project that vehicle have insulation montoring )";
CM_ SG_ 2550395887 ISOPosResis "正极绝缘值（多合一项目或者整车采绝缘的项目）
Positive insulation value(Project that vehicle have insulation montoring )";
CM_ SG_ 2550395887 ISONegResis "负极绝缘值（多合一项目或者整车采绝缘的项目）
Negative insulation value(Project that vehicle have insulation montoring )";
CM_ SG_ 2550395887 ISOReserved "Reserved(填充0)
Reserved(filled in 0)";
CM_ BO_ 2550263795 "BMU发送的VIN码请求
The VIN requirement message from BMU to VCU";
CM_ SG_ 2550263795 B2VRQVIN "BMS请求VIN码标志
VIN requirement flag";
CM_ SG_ 2550263795 B2VRQReserved1 "预留(填充0)
Reserved(filled in 0)";
CM_ SG_ 2550263795 B2VRQReserved2 "预留(填充0)
Reserved(filled in 0)";
CM_ BO_ 2564944879 "VCU发送到BMS的VIN(响应B2V_RQVIN，请求1次，响应3帧--3帧发送一次完整的VIN)
The VIN information from VCU to BMS(respond to the message B2V_RQVIN ）";
CM_ SG_ 2564944879 V2BVINFrameNo "VIN帧序号
Serial number of frame VIN";
CM_ SG_ 2564944879 V2BVINB1815 "车辆VIN码1，8，15字符(ASCII码)
Vehicle VIN 1,8,15 character（ASCII）";
CM_ SG_ 2564944879 V2BVINB2916 "车辆VIN码2，9，16字符(ASCII码)
Vehicle VIN 1,8,15 character（ASCII）";
CM_ SG_ 2564944879 V2BVINB31017 "车辆VIN码3，10，17字符(ASCII码)
Vehicle VIN 3,10,17character（ASCII）";
CM_ SG_ 2564944879 V2BVINB411 "车辆VIN码4，11字符(ASCII码)
Vehicle VIN 4,11character（ASCII）";
CM_ SG_ 2564944879 V2BVINB512 "车辆VIN码5，12字符(ASCII码)
Vehicle VIN 5,12character（ASCII）";
CM_ SG_ 2564944879 V2BVINB613 "车辆VIN码6，13字符(ASCII码)
Vehicle VIN 6,13character（ASCII）";
CM_ SG_ 2564944879 V2BVINB714 "车辆VIN码7，14字符(ASCII码)
Vehicle VIN 7,14character（ASCII）";
CM_ BO_ 2564943859 "BMS发送到车载终端的编码信息
The system code Information  from BMS to the vehicle terminal";
CM_ SG_ 2564943859 B2VSNFrameNo "电池编码信息帧序号
Battery Code number of frame VIN";
CM_ SG_ 2564943859 B2VSNSysCodeLength "电池编码长度
Length of battery code";
CM_ SG_ 2564943859 B2VSNSysCodeB171319 "电池编码(SN)字符1,7,13,19(ASCII)
Battery Code(SN) Character 1,7,13,19(ASCII)";
CM_ SG_ 2564943859 B2VSNSysCodeB281420 "电池编码(SN)字符2,8,14,20(ASCII)
Battery Code(SN) Character 2,8,14,20(ASCII)";
CM_ SG_ 2564943859 B2VSNSysCodeB391521 "电池编码(SN)字符3,9,15,21(ASCII)
Battery Code(SN) Character 3,9,15,21(ASCII)";
CM_ SG_ 2564943859 B2VSNSysCodeB4101622 "电池编码(SN)字符4,10,16,22(ASCII)
Battery Code(SN) Character4,10,16,22(ASCII)";
CM_ SG_ 2564943859 B2VSNSysCodeB5111723 "电池编码(SN)字符5,11,17,23(ASCII)
Battery Code(SN) Character 5,11,17,23(ASCII)";
CM_ SG_ 2564943859 B2VSNSysCodeB6121824 "电池编码(SN)字符6,12,18,24(ASCII)
Battery Code(SN) Character 6,12,18,24(ASCII)";
CM_ BO_ 2565009395 "电池包基本信息1
The Basic Battery Information-1 from BMS to VCU";
CM_ SG_ 2565009395 B2VBI1RateCap "电池包额定容量
Rated Capacity of Battery";
CM_ SG_ 2565009395 B2VBI1RateHVolt "电池包额定电压
Rated Voltage of Battery";
CM_ SG_ 2565009395 B2VBI1RatePower "电池包额定总能量
Rated total energy of Battery";
CM_ SG_ 2565009395 B2VBI1BattType "电池类型
Type of battery";
CM_ SG_ 2565009395 B2VBI1CoolType "电池冷却方式
Type of Battery Cooling mode";
CM_ SG_ 2565009395 B2VBI1BattManufacture "电池厂家
Battery manufacutre";
CM_ SG_ 2565009395 B2VBI1ProtocolEditionH "通讯协议版本高位（例：版本为3.1，则此处发3）
Porotocol Edition-high";
CM_ SG_ 2565009395 B2VBI1ProtocolEditionL "通讯协议版本低位（例：版本为3.1，则此处发1）
Porotocol Edition-low";
CM_ BO_ 2565074931 "电池包基本信息2
The Basic Battery Information-2 from BMS to VCU";
CM_ SG_ 2565074931 B2VBI2TotCSCNum "电池系统中CSC总的数目(电池监控单元数目)
Sum of CSC";
CM_ SG_ 2565074931 B2VBI2PackTotCellNum "PACK中单体电芯的总数目
Sum of cell in pack";
CM_ SG_ 2565074931 B2VBI2PackTotTempNum "PACK中电芯温度点(探针)的总数目
Sum of Temperature Probe in PACK";
CM_ SG_ 2565074931 B2VBI2HVBranchNum "电池系统高压支路数
High-voltage Branch of battery";
CM_ SG_ 2565074931 B2VBI2SingleHVBranchCellNum "电池系统单支路电芯数
Sum of cell in single branch";
CM_ SG_ 2565074931 B2VBI2BattSysNum "可充电储能系统数目（EV默认1，满足GB32960要求）
Sum of energy storage system(GBT 32960)";
CM_ SG_ 2565074931 B2VBI2BattSysSeqNum "可充电储能系统序号（EV默认1，满足GB32960要求）
Serial number of energy storage system(GBT 32960)";
CM_ BO_ 2565140467 "电池包基本信息3
The Basic Battery Information-3 from BMS to VCU";
CM_ SG_ 2565140467 B2VBI3PackAvaiMaxVolt "PACK可用电压上限(根据技术协议)
Maximum available voltage of battery pack";
CM_ SG_ 2565140467 B2VBI3PackAvaiMinVolt "PACK可用电压下限(根据技术协议)
Minimum available voltage of battery pack";
CM_ SG_ 2565140467 B2VBI3AvaiMaxSOC "PACK可用最高SOC(根据技术协议)
Maximum available SOC of battery pack";
CM_ SG_ 2565140467 B2VBI3AvaiMinSOC "PACK可用最低SOC(根据技术协议)
Minimum availableSOC of battery pack";
CM_ SG_ 2565140467 B2VBI3AvaiMaxTemp "PACK可用温度上限(根据技术协议)
Maximum available temperature of battery pack";
CM_ SG_ 2565140467 B2VBI3AvaiMinTemp "PACK可用温度下限(根据技术协议)
Minimum available temperature of battery pack";
CM_ BO_ 2562846707 "BMS的单体详细电压
The cell voltage information of BMS";
CM_ SG_ 2562846707 B2VVFrameNo "本帧起始单体电压序号（从1开始）
Cell serial number of this Frame(Started from 1)";
CM_ SG_ 2562846707 B2VVCellVoltN1 "本帧第1号电池电压（最后一帧发不满，则发送0xFFFF）
Voltage of No.1 cell  in this frame (Send 0xFFFF if the voltage value is invail)";
CM_ SG_ 2562846707 B2VVCellVoltN2 "本帧第2号电池电压（最后一帧发不满，则发送0xFFFF）
Voltage of No.2 cell  in this frame (Send 0xFFFF if the voltage value is invail)";
CM_ SG_ 2562846707 B2VVCellVoltN3 "本帧第3号电池电压（最后一帧发不满，则发送0xFFFF）
Voltage of No.3 cell  in this frame (Send 0xFFFF if the voltage value is invail)";
CM_ BO_ 2562912243 "BMS的电芯详细温度
The cell temperature information of BMS";
CM_ SG_ 2562912243 B2VTFrameNo "本帧起始单体温度序号（从1开始）
Temperature probe serial number of this Frame(Started from 1)";
CM_ SG_ 2562912243 B2VTCellTempN1 "本帧第1号电池温度（最后一帧发不满，则发送0xFF）
Temperature of No.1 probe  in this frame (Send 0xFF if the temperature value is invail)";
CM_ SG_ 2562912243 B2VTCellTempN2 "本帧第2号电池温度（最后一帧发不满，则发送0xFF）
Temperature of No.2 probe  in this frame (Send 0xFF if the temperature value is invail)";
CM_ SG_ 2562912243 B2VTCellTempN3 "本帧第3号电池温度（最后一帧发不满，则发送0xFF）
Temperature of No.3 probe  in this frame (Send 0xFF if the temperature value is invail)";
CM_ SG_ 2562912243 B2VTCellTempN4 "本帧第4号电池温度（最后一帧发不满，则发送0xFF）
Temperature of No.4 probe  in this frame (Send 0xFF if the temperature value is invail)";
CM_ SG_ 2562912243 B2VTCellTempN5 "本帧第5号电池温度（最后一帧发不满，则发送0xFF）
Temperature of No.5 probe  in this frame (Send 0xFF if the temperature value is invail)";
CM_ SG_ 2562912243 B2VTCellTempN6 "本帧第6号电池温度（最后一帧发不满，则发送0xFF）
Temperature of No.6 probe  in this frame (Send 0xFF if the temperature value is invail)";
CM_ BO_ 2558652403 "BMS发送GB32960中规定需要上传的故障
BMS send alarm specified in GBT32960.3";
CM_ SG_ 2558652403 B2VFult132960Reserved1 "预留(填充0)
Reserved(filled in 0)";
CM_ SG_ 2558652403 B2VFult1DelTemp "电芯温差异常报警
Excessive temperature differentials alarm";
CM_ SG_ 2558652403 B2VFult1OverTemp "电芯温度过高报警
Excess temperature alarm";
CM_ SG_ 2558652403 B2VFult1PackOverHVolt "PACK过压报警
Pack overhigh voltage alarm";
CM_ SG_ 2558652403 B2VFult1PackLowHVolt "PACK欠压报警
Low pack voltage too  alarm";
CM_ SG_ 2558652403 B2VFult1LowSOC "SOC过低报警
SOC too low alarm";
CM_ SG_ 2558652403 B2VFult1OverUcell "单体电压过高报警
Cell overhigh voltage alarm";
CM_ SG_ 2558652403 B2VFult1LowUcell "单体电压欠压报警
Cell voltage too low alarm";
CM_ SG_ 2558652403 B2VFult1LowInsRes "绝缘报警
Insulation resistance too low alarm";
CM_ SG_ 2558652403 B2VFult1UcellUniformity "电池一致性差报警
Cell high consistency alarm";
CM_ SG_ 2558652403 B2VFult1OverChg "车载储能装置过充报警
Energy system overcharged alarm";
CM_ SG_ 2558652403 B2VFult1OverSOC "SOC过高报警
SOC too high alarm";
CM_ SG_ 2558652403 B2VFult1SOCChangeFast "SOC跳变报警
SOC Jump alarm";
CM_ SG_ 2558652403 B2VFult1BatSysNotMatch "可充电储能系统不匹配报警
BMS not matched alarm";
CM_ SG_ 2558652403 B2VFult1HVILFault "高压互锁报警
HVIL alarm";
CM_ SG_ 2558652403 B2VFult1FaultNum32960 "GBT32960.3中规定的故障数目(当前时刻发生的)
Sum alarm specified in GBT32960.3(Current)";
CM_ SG_ 2558652403 B2VFult132960Reserved2 "预留(填充0)
Reserved(filled in 0)";
CM_ BO_ 2558717939 "BMS的故障信息2
BMS fault information";
CM_ SG_ 2558717939 B2VFult2FaultNum "BMS当前发生的故障总数目（包括GB32960中规定的故障数目）
Sum fault of BMS(Include GBT32960 fault)";
CM_ SG_ 2558717939 B2VFult2CellOverDischrg "电芯过放故障
Cell overdischarged alarm";
CM_ SG_ 2558717939 B2VFult2CellLowTemp "电芯低温报警
Cell low temperature alarm";
CM_ SG_ 2558717939 B2VFult2PackFireWarning "电池包火灾报警
Fire alarm";
CM_ SG_ 2558717939 B2VFult2OverDischrgCurr "放电电流超限报警
Pack overdischarged alarm";
CM_ SG_ 2558717939 B2VFult2OverChrgCurrInTheDrive "回充电流超限报警
Pack overcharged alarm";
CM_ SG_ 2558717939 B2VFult2CurrSensorErr "电流传感器故障
Current sensor fault";
CM_ SG_ 2558717939 B2VFult2PowerSupplyErr "BMS低压供电电压异常报警
BMS low-voltage power abnormal alarm";
CM_ SG_ 2558717939 B2VFult2TMSErr "热管理机组故障
TMS fault";
CM_ SG_ 2558717939 B2VFult2HeatungFilmErr "加热膜加热回路故障
The heating file fault";
CM_ SG_ 2558717939 B2VFult2PackSelfProtect "电池包自保护故障
Pack self-protection alarm";
CM_ SG_ 2558717939 B2VFult2MainLoopPrechrgErr "主回路预充或预检故障
Main-loop precharge or precheck fault";
CM_ SG_ 2558717939 B2VFult2AuxLoopPrechrgErr "辅件回路预充或预检故障
Aux-loop precharge or precheck fault";
CM_ SG_ 2558717939 B2VFult2ChrgInsLowErr "充电绝缘阻值低
Low insulation value alarm when in charging";
CM_ SG_ 2558717939 B2VFult2ACANLost "ACAN通讯故障
ACAN lost alarm";
CM_ SG_ 2558717939 B2VFult2InnerCommunicationErr "BMS内部通信故障
BMS inside communication fault";
CM_ SG_ 2558717939 B2VFult2DCDCErr "BMS-DC-DC故障
DCDC fault of BMS";
CM_ SG_ 2558717939 B2VFult2BranchBreakErr "支路断路故障报警
Branch break fault";
CM_ SG_ 2558717939 B2VFult2HeatRelayOpenErr "加热膜或TMS接触器故障无法闭合报警
Heat or TMS contactor open-circuit fault";
CM_ SG_ 2558717939 B2VFult2HeatRelayWeldErr "加热膜或TMS接触器故障无法断开报警
Heat or TMS contactor welded fault";
CM_ SG_ 2558717939 B2VFult2MainPosRelayOpenErr "主正接触器无法闭合故障报警
Main-Positive contactor open-circuit fault";
CM_ SG_ 2558717939 B2VFult2MainPosRelayWeldErr "主正接触器无法断开故障报警
Main-Positive contactor welded fault";
CM_ SG_ 2558717939 B2VFult2MainNegRelayOpenErr "主负接触器无法闭合故障报警
Main-Negative contactor open-circuit fault";
CM_ SG_ 2558717939 B2VFult2MainNegRelayWeldErr "主负接触器无法断开故障报警
Main-Negative contactor welded fault";
CM_ SG_ 2558717939 B2VFult2DCChrgPos1RelayOpenErr "直流充电A正接触器无法闭合故障报警
DC-Charge A positive contactor open-circuit fault";
CM_ SG_ 2558717939 B2VFult2DCChrgPos1RelayWeldErr "直流充电A正接触器无法断开故障报警
DC-Charge A positive contactor welded fault";
CM_ SG_ 2558717939 B2VFult2DCChrgNeg1RelayOpenErr "直流充电A负接触器无法闭合故障报警
DC-Charge A negative contactor open-circuit fault";
CM_ SG_ 2558717939 B2VFult2DCChrgNeg1RelayWeldErr "直流充电A负接触器无法断开故障报警
DC-Charge A negative contactor welded fault";
CM_ SG_ 2558717939 B2VFult2DCChrgPos2RelayOpenErr "直流充电B正接触器无法闭合故障报警
DC-Charge B positive contactor open-circuit fault";
CM_ SG_ 2558717939 B2VFult2DCChrgPos2RelayWeldErr "直流充电B正接触器无法断开故障报警
DC-Charge B positive contactor welded fault";
CM_ SG_ 2558717939 B2VFult2DCChrgNeg2RelayOpenErr "直流充电B负接触器无法闭合故障报警
DC-Charge B negative contactor open-circuit fault";
CM_ SG_ 2558717939 B2VFult2DCChrgNeg2RelayWeldErr "直流充电B负接触器无法断开故障报警
DC-Charge B negative contactor welded fault";
CM_ SG_ 2558717939 B2VFult2ACChrgPosRelayOpenErr "交流充电正接触器无法闭合故障报警
AC-Charge positive contactor open-circuit fault";
CM_ SG_ 2558717939 B2VFult2ACChrgPosRelayWeldErr "交流充电正接触器无法断开故障报警
AC-Charge positive contactor welded fault";
CM_ SG_ 2558717939 B2VFult2ACChrgNegRelayOpenErr "交流充电负接触器无法闭合故障报警
AC-Charge negative contactor open-circuit fault";
CM_ SG_ 2558717939 B2VFult2ACChrgNegRelayWeldErr "交流充电负接触器无法断开故障报警
AC-Charge negative contactor welded fault";
CM_ SG_ 2558717939 B2VFult2PantoChrgPosRelayOpenErr "集电弓正接触器无法闭合故障报警
Pantograph Charge positive contactor open-circuit fault";
CM_ SG_ 2558717939 B2VFult2PantoChrgPosRelayWeldErr "集电弓正接触器无法断开故障报警
Pantograph Charge positive contactor welded fault";
CM_ SG_ 2558717939 B2VFult2PantoChrgNegRelayOpenErr "集电弓负接触器无法闭合故障报警
Pantograph Charge negative contactor open-circuit fault";
CM_ SG_ 2558717939 B2VFult2PantoChrgNegRelayWeldErr "集电弓负接触器无法断开故障报警
Pantograph Charge negative contactor welded fault";
CM_ SG_ 2558717939 B2VFult2ChrgConnectErr "插枪连接信号异常
Charge gun connection abnormal alarm";
CM_ SG_ 2558717939 B2VFlt2OverDschrgCrrWhnInChrg "充电时放电电流过大
Current overdischarged when in charging";
CM_ SG_ 2558717939 B2VFult2OverChrgCurrInTheChrg "充电电流超限报警
Charge current overload alarm";
CM_ SG_ 2558717939 B2VFult2ChrgNTCErr "充电插座NTC故障
DC charge socket fault";
CM_ SG_ 2558717939 B2VFult2ChrgNTCTempOver "充电插座过温报警
Over-temperature alarm of DC charge socket";
CM_ SG_ 2558717939 B2VFult2ELockErr "电子锁故障
E-lock fault";
CM_ SG_ 2558717939 B2VFult2FireDetectorErr "火警探测器故障
Fire detector";
CM_ SG_ 2558717939 B2VFult2ContiChrgCurrOverLoad "持续回充过流故障
Continued Charge current over load  alarm";
CM_ SG_ 2558717939 B2VFult2SOCDifferErr "SOC差异过大
Excessive SOC differentials alarm";
CM_ SG_ 2558717939 B2VFult2ContiDischrgCurrOverLoad "持续放电过流故障
Continued Discharge current over load  alarm";
CM_ SG_ 2558717939 B2VFult2Reserved1 "预留故障1（填充0）
Reserved-1(filled in 0)";
CM_ SG_ 2558717939 B2VFult2Reserved2 "预留故障2（填充0）
Reserved-2(filled in 0)";
CM_ BO_ 2558783475 "BMS的状态数据1
The status Data-1 of BMS";
CM_ SG_ 2558783475 B2VST1MainPosRelaySt "主正继电器状态(如继电器状态由BMS检测)
Status of main-positive contactor";
CM_ SG_ 2558783475 B2VST1MainNegRelaySt "主负继电器状态(如继电器状态由BMS检测)
Status of main-negative contactor";
CM_ SG_ 2558783475 B2VST1PrechrgRelaySt "主回路预充或预检继电器状态(如继电器状态由BMS检测)
Status of main-loop precharge or precheck contactor";
CM_ SG_ 2558783475 B2VST1DCChrgPos1RelaySt "直流充正继电器1状态(如继电器状态由BMS检测)
Status of DC-charge positive-1 contactor";
CM_ SG_ 2558783475 B2VST1DCChrgNeg1RelaySt "直流充负继电器1状态(如继电器状态由BMS检测)
Status of DC-charge negative-1 contactor";
CM_ SG_ 2558783475 B2VST1DCChrgPos2RelaySt "直流充正继电器2状态(如继电器状态由BMS检测)
Status of DC-charge positive-2 contactor";
CM_ SG_ 2558783475 B2VST1DCChrgNeg2RelaySt "直流充负继电器2状态(如继电器状态由BMS检测)
Status of DC-charge negative-2 contactor";
CM_ SG_ 2558783475 B2VST1HeatPosRelaySt "加热正继电器状态(如继电器状态由BMS检测)
Status of heat positive contactor";
CM_ SG_ 2558783475 B2VST1HeatNegRelaySt "加热负继电器状态(如继电器状态由BMS检测)
Status of heat negative contactor";
CM_ SG_ 2558783475 B2VST1PantoChrgPosRelaySt "集电弓正继电器状态(如继电器状态由BMS检测)
Status of pantograph charge positive contactor";
CM_ SG_ 2558783475 B2VST1PantoChrgNegRelaySt "集电弓负继电器状态(如继电器状态由BMS检测)
Status of pantograph charge negative contactor";
CM_ SG_ 2558783475 B2VST1ACChrgPosRelaySt "交流正继电器状态(如继电器状态由BMS检测)
Status of AC-charge positive contactor";
CM_ SG_ 2558783475 B2VST1ACChrgNegRelaySt "交流负继电器状态(如继电器状态由BMS检测)
Status of AC-charge negative contactor";
CM_ SG_ 2558783475 B2VST1Aux1RelaySt "附件1继电器状态(如继电器状态由BMS检测)
Status of  auxiliary-1 contactor";
CM_ SG_ 2558783475 B2VST1Aux2RelaySt "附件2继电器状态(如继电器状态由BMS检测)
Status of  auxiliary-2 contactor";
CM_ SG_ 2558783475 B2VST1Aux3RelaySt "附件3继电器状态(如继电器状态由BMS检测)
Status of  auxiliary-3 contactor";
CM_ SG_ 2558783475 B2VST1BMSHVStatus "BMS当前高压状态
BMS high-voltage status";
CM_ SG_ 2558783475 B2VST1BMSBalanceStatus "BMS当前均衡状态
BMS balance status";
CM_ SG_ 2558783475 B2VST1DCChrgConnectSt "直流充电枪连接状态
DC-Charge gun connect status";
CM_ SG_ 2558783475 B2VST1PantoChrgConnectSt "集电弓充电枪连接状态
Pantograph Charge gun connect status";
CM_ SG_ 2558783475 B2VST1ACChrgConnectSt "交流充电枪连接状态
AC-Charge gun connect status";
CM_ SG_ 2558783475 B2VST1ChrgMode "BMS当前充电模式
BMS charge mode";
CM_ SG_ 2558783475 B2VST1ChrgStatus "充电状态
BMS charge status";
CM_ SG_ 2558783475 B2VST1HeatingStatus "当前加热状态
BMS heat status";
CM_ SG_ 2558783475 B2VST1CoolingStatus "当前冷却状态
BMS cooling status";
CM_ SG_ 2558783475 B2VST1RechrgCycels "充电次数
BMS charge cycles";
CM_ BO_ 2558849011 "BMS的状态数据2
The status Data-2 of BMS";
CM_ SG_ 2558849011 B2VST2SOC "电池包SOC
SOC";
CM_ SG_ 2558849011 B2VST2SOH "电池包SOH
SOH";
CM_ SG_ 2558849011 B2VST2PackCurrent "电池包总电流，充电为负值，放电为正值
Pack current";
CM_ SG_ 2558849011 B2VST2PackInsideVolt "电池包内侧电压
Pack inside high-voltage";
CM_ SG_ 2558849011 B2VST2FaultCode "故障码
Fault code";
CM_ SG_ 2558849011 B2VST2FaultLevel "当前最高故障等级
Highest fault level";
CM_ SG_ 2558849011 B2VST2RqHVPoerOff "BMS下高压请求
Require high-voltage poweron-ff";
CM_ SG_ 2558849011 B2VST2Life "BMS生命信号
BMS life signal";
CM_ BO_ 2558914547 "BMS的状态数据3
The status Data-4 of BMS";
CM_ SG_ 2558914547 B2VST3PosInsRes "BMS正极绝缘值
BMS positive insulation value";
CM_ SG_ 2558914547 B2VST3NegInsRes "BMS负极绝缘值
BMS negative insulation value";
CM_ SG_ 2558914547 B2VST3SysInsRes "BMS系统绝缘值
BMS system insulation value";
CM_ SG_ 2558914547 B2VST3InsDetectorSt "BMS绝缘检测状态
BMS insulation detection status";
CM_ SG_ 2558914547 B2VST3Reserved1 "预留（填充0）
Reserved(filled in 0)";
CM_ BO_ 2558980083 "BMS的状态数据4
The status Data-4 of BMS";
CM_ SG_ 2558980083 B2VST4MaxTemp "电芯温度最大值
Maximum cell temperatuer in pack";
CM_ SG_ 2558980083 B2VST4MinTemp "电芯温度最小值
Minimum cell temperatuer in pack";
CM_ SG_ 2558980083 B2VST4AvgTemp "电芯温度平均值
Average cell temperatuer in pack";
CM_ SG_ 2558980083 B2VST4MaxTempCSCNo "最高温度探针所在的CSC编号
CSC serial number  with  maximum cell temperture";
CM_ SG_ 2558980083 B2VST4MaxTempPosition "最高温度探针在系统中的位置
Serial number of maximum cell temperture probe in pack";
CM_ SG_ 2558980083 B2VST4MinTempCSCNo "最低温度探针所在的CSC编号
CSC serial number  with minimum cell temperture";
CM_ SG_ 2558980083 B2VST4MinTempPosition "最低温度探针在系统中的位置
Serial number of minimum cell temperture probe in pack";
CM_ SG_ 2558980083 B2VST4Reserved1 "预留（填充0）
Reserved(filled in 0)";
CM_ BO_ 2559045619 "BMS的状态数据5
The status Data-5 of BMS";
CM_ SG_ 2559045619 B2VST5MaxUcell "电芯电压最大值
Maximum voltage of cell";
CM_ SG_ 2559045619 B2VST5MinUcell "电芯电压最小值
Minimum voltage of cell";
CM_ SG_ 2559045619 B2VST5AvgUcell "电芯电压平均值
Average voltage of cell";
CM_ SG_ 2559045619 B2VST5Reserved1 "预留（填充0）
Reserved(filled in 0)";
CM_ BO_ 2559111155 "BMS的状态数据6
The status Data-6 of BMS";
CM_ SG_ 2559111155 B2VST6MaxUcellCSCNo "最高电压电芯在的CSC编号
CSC serial number  with  maximum cell voltage";
CM_ SG_ 2559111155 B2VST6MaxUcellPosition "最高电压电芯在系统中的位置
Serial number of maximum cell voltage in pack";
CM_ SG_ 2559111155 B2VST6MinUcellCSCNo "最低电压电芯在的CSC编号
CSC serial number  with  minimum cell voltage";
CM_ SG_ 2559111155 B2VST6MinUcellPosition "最低电压电芯在系统中的位置
Serial number of minimum cell voltage in  CSC";
CM_ SG_ 2559111155 B2VST6Reserved1 "预留（填充0）
Reserved(filled in 0)";
CM_ BO_ 2559176691 "BMS的状态数据7
The status Data-7 of BMS";
CM_ SG_ 2559176691 B2VST7Gun1DCPosTemp "直流充电A枪DC+温度传感器温度（无该温度传感器发默认发0xFF）
DC-Charged A-gun positive temperature";
CM_ SG_ 2559176691 B2VST7Gun1DCNegTemp "直流充电A枪DC-温度传感器温度（无该温度传感器发默认发0xFF）
DC-Charged A-gun negative temperature";
CM_ SG_ 2559176691 B2VST7Gun2DCPosTemp "直流充电B枪DC+温度传感器温度（无该温度传感器发默认发0xFF）
DC-Charged B-gun positive temperature";
CM_ SG_ 2559176691 B2VST7Gun2DCNegTemp "直流充电B枪DC-温度传感器温度（无该温度传感器发默认发0xFF）
DC-Charged B-gun negative temperature";
CM_ SG_ 2559176691 B2VST7GunACPosTemp "交流充电枪AC+温度传感器温度（若交流充电只有一个温度传感器，则默认为AC+）
AC-Charged gun positive temperature";
CM_ SG_ 2559176691 B2VST7GunACNegTemp "交流充电枪AC-温度传感器温度（若交流充电只有一个温度传感器，则默认为AC+）
AC-Charged gun negative temperature";
CM_ SG_ 2559176691 B2VST7Reserved1 "预留（填充0）
Reserved(filled in 0)";
CM_ SG_ 2559176691 B2VST7Reserved2 "预留（填充0）
Reserved(filled in 0)";
CM_ BO_ 2562977779 "BMS的电量相关数据
BMS  electric quantity information";
CM_ SG_ 2562977779 B2VTotChgEnergy "累计充电电量
Accumulated charged electric quantity";
CM_ SG_ 2562977779 B2VTotDischgEnergy "累计放电电量
Accumulated discharged electric quantity";
CM_ SG_ 2562977779 B2VSingleChgEnergy "单次充电电量(充电机在线时)
Single charged electric quantity (charger online)";
CM_ BO_ 2563043315 "BMS的允许充放电电流
BMS allow maximum current";
CM_ SG_ 2563043315 B2VAvailInpulseDischrgCurr "BMS允许的脉冲放电电流（瞬时电流）
Battery allow maximum discharge current(Pulse）";
CM_ SG_ 2563043315 B2VAvailInpulseChrgCurr "BMS允许的脉冲回充电流（瞬时电流）
Battery allow maximum feedback charge current(Pulse）";
CM_ SG_ 2563043315 B2VAvailFollowChrgCurr "BMS允许的持续回充电流（燃料电池或PHEV才有）
Battery allow maximum  sustained discharg current(PHEV or Fuel battery vehicle）";
CM_ SG_ 2563043315 B2VAvailFollowDishrgCurr "BMS允许的持续放电电流（V2V或者储能才有）
Battery allow maximum  sustained discharg current(V2V or storage vehicle）";
CM_ BO_ 2563108851 "BMU发送到VCU的充电状态
The charge status of BMS";
CM_ SG_ 2563108851 B2VSVoltageSet "充电电压设置
Charge voltage requirement";
CM_ SG_ 2563108851 B2VSCurrentSet "充电电流设置
Charge current requirement";
CM_ SG_ 2563108851 B2VSChargeSta "充电状态
Charge Status";
CM_ SG_ 2563108851 B2VChargeInfoReserved1 "预留(填充0)
Reserved(filled in 0）";
CM_ BO_ 2550461423 "VCU发送给BMU的充电状态
The charge status of VCU";
CM_ SG_ 2550461423 V2BNVoltageOutput "交流充电机电压输出
Output voltage of AC Charger";
CM_ SG_ 2550461423 V2BNCurrentOutput "交流充电机电流输出
Output current of  AC Charger";
CM_ SG_ 2550461423 V2BFChargerHardware "交流充电机硬件故障（BMU终止充电流程，待故障消失后重启充电流程）
Hardware fualt of  AC charger(BMU will forbid charging until  fault disappeared，and restart  charging process）";
CM_ SG_ 2550461423 V2BFChargerOverTemp "交流充电机温度过高警告（BMS限制充电功率）
Over-temperature alarm of AC charger(BMS will limit charging power）";
CM_ SG_ 2550461423 V2BFChargerInputVoltage "交流充电机输入电压异常（BMU终止充电流程，待故障消失后重启充电流程）
Input voltage of AC Charger  is abnormal(BMU will don't charging until  fault disappeared，and restart  charging process)";
CM_ SG_ 2550461423 V2BStChargerReady "交流充电机初始化状态(充电机上电后自检，自检完成后将自检状态发给BMS)
Initial state of  AC Charger (charger will self-check when power on,charger will send  result when completing  self-check)";
CM_ SG_ 2550461423 V2BStChargerStart "交流充电机工作状态(当车载充电机接收到BMS发送的启动命令后，反馈自己运行的状态信息)
Working state of  AC Charger(when on-board charger receive  starting command from BMS,it will feedback running State)";
CM_ SG_ 2550461423 V2BFChargerCAN "充电机通讯故障(BMS终止充电流程，待故障消失后重启充电过程)
Charger Communicating Fault(BMU will don't charging until  fault disappeared，and restart  charging process）";
CM_ SG_ 2550461423 V2BStChargeAllow "充电允许信号
Charge control command";
CM_ SG_ 2550461423 V2BStChargeMode "充电模式
Charge Mode";
CM_ SG_ 2550461423 V2BChargeStatusReserved1 "预留(填充0)
Reserved(filled in 0）";
CM_ BO_ 2559242227 "多合一项目BMS请求指令（多合一项目才发送）
contactor command from BMS to VCU（Project that multi-contactor arrange in one high-voltage box）";
CM_ SG_ 2559242227 B2VChrgRelayCMD "充电继电器请求（若该项目为多合一项目，且该项目存在该继电器）
Charge contactor command from BMS to VCU（Project that multi-contactor arrange in one high-voltage box）";
CM_ SG_ 2559242227 B2VHeatPosRelayCMD "加热正继电器请求（若该项目为多合一项目，且该项目存在该继电器）
Heat positive contactor command from BMS to VCU（Project that multi-contactor arrange in one high-voltage box）";
CM_ SG_ 2559242227 B2VHeatNegRelayCMD "加热负继电器请求（若该项目为多合一项目，且该项目存在该继电器）
Heat negative contactor command from BMS to VCU（Project that multi-contactor arrange in one high-voltage box）";
CM_ SG_ 2559242227 B2VMainPosRelayCMD "主负继电器请求（若该项目为多合一项目，且该项目存在该继电器）
Main-loop negative contactor command from BMS to VCU（Project that multi-contactor arrange in one high-voltage box）";
CM_ SG_ 2559242227 B2VInsForbidCMD "绝缘禁止请求（多合一项目）
Forbid insulation detection （Project that multi-contactor arrange in one high-voltage box）";
CM_ SG_ 2559242227 B2VMainNegRelayCoilSt "主负继电器线圈状态（多合一项目）
Coil status of main-loop negative contactor（Project that multi-contactor arrange in one high-voltage box）";
CM_ SG_ 2559242227 B2VStatusOfRelayReserved1 "预留(填充0)
Reserved(filled in 0）";
CM_ SG_ 2559242227 B2VStatusOfRelayReserved2 "预留(填充0)
Reserved(filled in 0）";
CM_ BO_ 2566866420 "BMS发送到TMS的数据（水冷项目）
The  information from  BMS to TMS";
CM_ SG_ 2566866420 B2TRQSetModeA "BMS请求设定模式
Working mode command from BMS to TMS";
CM_ SG_ 2566866420 B2TRQHVA "高压请求
High-voltage command from BMS to TMS";
CM_ SG_ 2566866420 B2TChgSTA "充电状态
BMS charge status";
CM_ SG_ 2566866420 B2TBMSHVRelaySTA "BMS高压继电器状态
BMS high-voltage contactor status";
CM_ SG_ 2566866420 B2TBMSHVVoltA "BMS当前电压
Pack voltage";
CM_ SG_ 2566866420 B2TBMSR1 "预留(填充0)
Reserved(filled in 0）";
CM_ SG_ 2566866420 B2TSetTempA "设定温度
Setting temperature";
CM_ SG_ 2566866420 B2TBMSR2 "预留(填充0)
Reserved(filled in 0）";
CM_ SG_ 2566866420 B2TMBMSALIVA "BMS生命帧(备选项)
BMS life signal（Reserved）";
CM_ SG_ 2566866420 B2TMCRCA "CRC校验值(备选项)
CRC（Reserved）";
CM_ BO_ 2566897978 "TMS发送到BMS的数据（水冷项目）
The  information from   TMS to BMS";
CM_ SG_ 2566897978 T2BWorkStatusA "TMS工作状态
TMS work status";
CM_ SG_ 2566897978 T2BTMSHVRelaySTA "TMS的继电器状态
TMS contactor status";
CM_ SG_ 2566897978 TM2BInfoReserved1 "预留(填充0)
Reserved(filled in 0）";
CM_ SG_ 2566897978 TM2BOutletTempA "TMS出水温度(机组到电池)
TMS outlet water temperature（From TMS to pack）";
CM_ SG_ 2566897978 TM2BInletTempA "TMS进水温度(电池到机组)
TMS flooding water temperature（From TMS to pack）";
CM_ SG_ 2566897978 TM2BInfoReserved2 "预留(填充0)
Reserved(filled in 0）";
CM_ SG_ 2566897978 TM2BRQPowerA "水冷机组需求功率
TMS requirement power";
CM_ SG_ 2566897978 TM2BFaultCodeA "TMS故障代码(出现1种以上循环发送)
TMS fault code";
CM_ SG_ 2566897978 TM2BFaultLevelA "TMS故障等级
TMS fault level";
CM_ BO_ 2566911990 "灭火控制器发送的广播报文";
CM_ SG_ 2566911990 Fire2BBoxNo "电池箱号（探测器编号，轮询发送）";
CM_ SG_ 2566911990 Fire2BBomType "探测器启动灭火弹类型";
CM_ SG_ 2566911990 Fire2BFaultLevel "火情级别";
CM_ SG_ 2566911990 Fire2BFaultCode "故障码";
CM_ SG_ 2566911990 Fire2BValveCmd "子阀打开或关闭命令";
CM_ SG_ 2566911990 Fire2BSysFaultCode "灭火系统故障码";
CM_ SG_ 2566911990 Fire2BReserved2 "预留";
CM_ SG_ 2566911990 Fire2BRollingCounter "报文RollingCounter（0~15）";
BA_DEF_ SG_  "GenSigTimeoutTime_BMU" INT 0 100000;
BA_DEF_ SG_  "GenSigSendType" ENUM  "Cyclic","OnWrite","OnWriteWithRepetition","OnChange","OnChangeWithRepetition","IfActive","IfActiveWithRepetition","NoSigSendType","NotUsed","Event","CE","CA","NotUsed";
BA_DEF_ SG_  "GenSigStartValue" INT 0 0;
BA_DEF_ BO_  "GenMsgSendType" ENUM  "Cyclic","CA","CE","Event","NotUsed","NotUsed","NotUsed","IfActive","NoMsgSendType","NotUsed";
BA_DEF_ BO_  "GenMsgDelayTime" INT 0 1000;
BA_DEF_ BO_  "GenMsgILSupport" ENUM  "No","Yes";
BA_DEF_ BU_  "NmNode" ENUM  "No","Yes";
BA_DEF_  "DBName" STRING ;
BA_DEF_  "Manufacturer" STRING ;
BA_DEF_  "NmBaseAddress" HEX 0 1279;
BA_DEF_DEF_  "GenSigTimeoutTime_BMU" 0;
BA_DEF_DEF_  "GenSigSendType" "OnWrite";
BA_DEF_DEF_  "GenSigStartValue" 0;
BA_DEF_DEF_  "GenMsgSendType" "NoMsgSendType";
BA_DEF_DEF_  "GenMsgDelayTime" 0;
BA_DEF_DEF_  "GenMsgILSupport" "Yes";
BA_DEF_DEF_  "NmNode" "Yes";
BA_DEF_DEF_  "DBName" "";
BA_DEF_DEF_  "Manufacturer" "CATL";
BA_DEF_DEF_  "NmBaseAddress" 1024;
BA_ "DBName" "CATL_Protocol_ACAN_V34_210705";
BA_ "GenSigTimeoutTime_BMU" SG_ 2550330351 V2BCMDLifeSignal 10000;
BA_ "GenSigTimeoutTime_BMU" SG_ 2550330351 V2BCMDHVOnOff 10000;
BA_ "GenSigTimeoutTime_BMU" SG_ 2550330351 V2BCMDAux1OnOff 10000;
BA_ "GenSigTimeoutTime_BMU" SG_ 2550330351 V2BCMDAux2OnOff 10000;
BA_ "GenSigTimeoutTime_BMU" SG_ 2550330351 V2BCMDAux3OnOff 10000;
BA_ "GenSigTimeoutTime_BMU" SG_ 2550330351 V2BCMDVehicleSpeed 10000;
BA_ "GenSigTimeoutTime_BMU" SG_ 2550330351 V2BCMDBatteryContactorPosST 10000;
BA_ "GenSigTimeoutTime_BMU" SG_ 2550330351 V2BCMDBatteryContactorPosFlt 10000;
BA_ "GenSigTimeoutTime_BMU" SG_ 2550330351 V2BCMDBatteryContactorNegST 10000;
BA_ "GenSigTimeoutTime_BMU" SG_ 2550330351 V2BCMDBatteryContactorNegFlt 10000;
BA_ "GenSigTimeoutTime_BMU" SG_ 2550330351 V2BCMDDCChargeContactorPosST 10000;
BA_ "GenSigTimeoutTime_BMU" SG_ 2550330351 V2BCMDDCChargeContactorPosFlt 10000;
BA_ "GenSigTimeoutTime_BMU" SG_ 2550330351 V2BCMDDCChargeContactorNegST 10000;
BA_ "GenSigTimeoutTime_BMU" SG_ 2550330351 V2BCMDDCChargeContactorNegFlt 10000;
BA_ "GenSigTimeoutTime_BMU" SG_ 2550330351 V2BCMDPantographContactorPosST 10000;
BA_ "GenSigTimeoutTime_BMU" SG_ 2550330351 V2BCMDPantographContactorPosFlt 10000;
BA_ "GenSigTimeoutTime_BMU" SG_ 2550330351 V2BCMDPantographContactorNegST 10000;
BA_ "GenSigTimeoutTime_BMU" SG_ 2550330351 V2BCMDPantographContactorNegFlt 10000;
BA_ "GenSigTimeoutTime_BMU" SG_ 2550330351 V2BCMDCharge1RelayST 10000;
BA_ "GenSigTimeoutTime_BMU" SG_ 2550330351 V2BCMDCharge1RelayFlt 10000;
BA_ "GenSigTimeoutTime_BMU" SG_ 2550330351 V2BCMDCharge2RelayST 10000;
BA_ "GenSigTimeoutTime_BMU" SG_ 2550330351 V2BCMDCharge2RelayFlt 10000;
BA_ "GenSigTimeoutTime_BMU" SG_ 2550330351 V2BCMDAux4RelayST 10000;
BA_ "GenSigTimeoutTime_BMU" SG_ 2550330351 V2BCMDAux4RelayFlt 10000;
BA_ "GenSigTimeoutTime_BMU" SG_ 2550330351 V2BCMDReserved1 10000;
BA_ "GenSigTimeoutTime_BMU" SG_ 2550330351 V2BCMDReserved2 10000;
BA_ "GenSigTimeoutTime_BMU" SG_ 2550395887 ISOWorkStatus 10000;
BA_ "GenSigTimeoutTime_BMU" SG_ 2550395887 ISOFaultLevel 10000;
BA_ "GenSigTimeoutTime_BMU" SG_ 2550395887 ISOPosResis 10000;
BA_ "GenSigTimeoutTime_BMU" SG_ 2550395887 ISONegResis 10000;
BA_ "GenSigTimeoutTime_BMU" SG_ 2550395887 ISOReserved 10000;
BA_ "GenSigTimeoutTime_BMU" SG_ 2550263795 B2VRQVIN 10000;
BA_ "GenSigTimeoutTime_BMU" SG_ 2550263795 B2VRQReserved1 10000;
BA_ "GenSigTimeoutTime_BMU" SG_ 2550263795 B2VRQReserved2 10000;
BA_ "GenSigTimeoutTime_BMU" SG_ 2564944879 V2BVINFrameNo 10000;
BA_ "GenSigTimeoutTime_BMU" SG_ 2564944879 V2BVINB1815 10000;
BA_ "GenSigTimeoutTime_BMU" SG_ 2564944879 V2BVINB2916 10000;
BA_ "GenSigTimeoutTime_BMU" SG_ 2564944879 V2BVINB31017 10000;
BA_ "GenSigTimeoutTime_BMU" SG_ 2564944879 V2BVINB411 10000;
BA_ "GenSigTimeoutTime_BMU" SG_ 2564944879 V2BVINB512 10000;
BA_ "GenSigTimeoutTime_BMU" SG_ 2564944879 V2BVINB613 10000;
BA_ "GenSigTimeoutTime_BMU" SG_ 2564944879 V2BVINB714 10000;
BA_ "GenSigTimeoutTime_BMU" SG_ 2564943859 B2VSNFrameNo 10000;
BA_ "GenSigTimeoutTime_BMU" SG_ 2564943859 B2VSNSysCodeLength 10000;
BA_ "GenSigTimeoutTime_BMU" SG_ 2564943859 B2VSNSysCodeB171319 10000;
BA_ "GenSigTimeoutTime_BMU" SG_ 2564943859 B2VSNSysCodeB281420 10000;
BA_ "GenSigTimeoutTime_BMU" SG_ 2564943859 B2VSNSysCodeB391521 10000;
BA_ "GenSigTimeoutTime_BMU" SG_ 2564943859 B2VSNSysCodeB4101622 10000;
BA_ "GenSigTimeoutTime_BMU" SG_ 2564943859 B2VSNSysCodeB5111723 10000;
BA_ "GenSigTimeoutTime_BMU" SG_ 2564943859 B2VSNSysCodeB6121824 10000;
BA_ "GenSigTimeoutTime_BMU" SG_ 2565009395 B2VBI1RateCap 10000;
BA_ "GenSigTimeoutTime_BMU" SG_ 2565009395 B2VBI1RateHVolt 10000;
BA_ "GenSigTimeoutTime_BMU" SG_ 2565009395 B2VBI1RatePower 10000;
BA_ "GenSigTimeoutTime_BMU" SG_ 2565009395 B2VBI1BattType 10000;
BA_ "GenSigTimeoutTime_BMU" SG_ 2565009395 B2VBI1CoolType 10000;
BA_ "GenSigTimeoutTime_BMU" SG_ 2565009395 B2VBI1BattManufacture 10000;
BA_ "GenSigTimeoutTime_BMU" SG_ 2565009395 B2VBI1ProtocolEditionH 10000;
BA_ "GenSigTimeoutTime_BMU" SG_ 2565009395 B2VBI1ProtocolEditionL 10000;
BA_ "GenSigTimeoutTime_BMU" SG_ 2565074931 B2VBI2TotCSCNum 10000;
BA_ "GenSigTimeoutTime_BMU" SG_ 2565074931 B2VBI2PackTotCellNum 10000;
BA_ "GenSigTimeoutTime_BMU" SG_ 2565074931 B2VBI2PackTotTempNum 10000;
BA_ "GenSigTimeoutTime_BMU" SG_ 2565074931 B2VBI2HVBranchNum 10000;
BA_ "GenSigTimeoutTime_BMU" SG_ 2565074931 B2VBI2SingleHVBranchCellNum 10000;
BA_ "GenSigTimeoutTime_BMU" SG_ 2565074931 B2VBI2BattSysNum 10000;
BA_ "GenSigTimeoutTime_BMU" SG_ 2565074931 B2VBI2BattSysSeqNum 10000;
BA_ "GenSigTimeoutTime_BMU" SG_ 2565140467 B2VBI3PackAvaiMaxVolt 10000;
BA_ "GenSigTimeoutTime_BMU" SG_ 2565140467 B2VBI3PackAvaiMinVolt 10000;
BA_ "GenSigTimeoutTime_BMU" SG_ 2565140467 B2VBI3AvaiMaxSOC 10000;
BA_ "GenSigTimeoutTime_BMU" SG_ 2565140467 B2VBI3AvaiMinSOC 10000;
BA_ "GenSigTimeoutTime_BMU" SG_ 2565140467 B2VBI3AvaiMaxTemp 10000;
BA_ "GenSigStartValue" SG_ 2565140467 B2VBI3AvaiMaxTemp 40;
BA_ "GenSigTimeoutTime_BMU" SG_ 2565140467 B2VBI3AvaiMinTemp 10000;
BA_ "GenSigStartValue" SG_ 2565140467 B2VBI3AvaiMinTemp 40;
BA_ "GenSigTimeoutTime_BMU" SG_ 2562846707 B2VVFrameNo 10000;
BA_ "GenSigTimeoutTime_BMU" SG_ 2562846707 B2VVCellVoltN1 10000;
BA_ "GenSigTimeoutTime_BMU" SG_ 2562846707 B2VVCellVoltN2 10000;
BA_ "GenSigTimeoutTime_BMU" SG_ 2562846707 B2VVCellVoltN3 10000;
BA_ "GenSigTimeoutTime_BMU" SG_ 2562912243 B2VTFrameNo 10000;
BA_ "GenSigTimeoutTime_BMU" SG_ 2562912243 B2VTCellTempN1 10000;
BA_ "GenSigStartValue" SG_ 2562912243 B2VTCellTempN1 40;
BA_ "GenSigTimeoutTime_BMU" SG_ 2562912243 B2VTCellTempN2 10000;
BA_ "GenSigStartValue" SG_ 2562912243 B2VTCellTempN2 40;
BA_ "GenSigTimeoutTime_BMU" SG_ 2562912243 B2VTCellTempN3 10000;
BA_ "GenSigStartValue" SG_ 2562912243 B2VTCellTempN3 40;
BA_ "GenSigTimeoutTime_BMU" SG_ 2562912243 B2VTCellTempN4 10000;
BA_ "GenSigStartValue" SG_ 2562912243 B2VTCellTempN4 40;
BA_ "GenSigTimeoutTime_BMU" SG_ 2562912243 B2VTCellTempN5 10000;
BA_ "GenSigStartValue" SG_ 2562912243 B2VTCellTempN5 40;
BA_ "GenSigTimeoutTime_BMU" SG_ 2562912243 B2VTCellTempN6 10000;
BA_ "GenSigStartValue" SG_ 2562912243 B2VTCellTempN6 40;
BA_ "GenSigTimeoutTime_BMU" SG_ 2558652403 B2VFult132960Reserved1 10000;
BA_ "GenSigTimeoutTime_BMU" SG_ 2558652403 B2VFult1DelTemp 10000;
BA_ "GenSigTimeoutTime_BMU" SG_ 2558652403 B2VFult1OverTemp 10000;
BA_ "GenSigTimeoutTime_BMU" SG_ 2558652403 B2VFult1PackOverHVolt 10000;
BA_ "GenSigTimeoutTime_BMU" SG_ 2558652403 B2VFult1PackLowHVolt 10000;
BA_ "GenSigTimeoutTime_BMU" SG_ 2558652403 B2VFult1LowSOC 10000;
BA_ "GenSigTimeoutTime_BMU" SG_ 2558652403 B2VFult1OverUcell 10000;
BA_ "GenSigTimeoutTime_BMU" SG_ 2558652403 B2VFult1LowUcell 10000;
BA_ "GenSigTimeoutTime_BMU" SG_ 2558652403 B2VFult1LowInsRes 10000;
BA_ "GenSigTimeoutTime_BMU" SG_ 2558652403 B2VFult1UcellUniformity 10000;
BA_ "GenSigTimeoutTime_BMU" SG_ 2558652403 B2VFult1OverChg 10000;
BA_ "GenSigTimeoutTime_BMU" SG_ 2558652403 B2VFult1OverSOC 10000;
BA_ "GenSigTimeoutTime_BMU" SG_ 2558652403 B2VFult1SOCChangeFast 10000;
BA_ "GenSigTimeoutTime_BMU" SG_ 2558652403 B2VFult1BatSysNotMatch 10000;
BA_ "GenSigTimeoutTime_BMU" SG_ 2558652403 B2VFult1HVILFault 10000;
BA_ "GenSigTimeoutTime_BMU" SG_ 2558652403 B2VFult1FaultNum32960 10000;
BA_ "GenSigTimeoutTime_BMU" SG_ 2558652403 B2VFult132960Reserved2 10000;
BA_ "GenSigTimeoutTime_BMU" SG_ 2558717939 B2VFult2FaultNum 10000;
BA_ "GenSigTimeoutTime_BMU" SG_ 2558717939 B2VFult2CellOverDischrg 10000;
BA_ "GenSigTimeoutTime_BMU" SG_ 2558717939 B2VFult2CellLowTemp 10000;
BA_ "GenSigTimeoutTime_BMU" SG_ 2558717939 B2VFult2PackFireWarning 10000;
BA_ "GenSigTimeoutTime_BMU" SG_ 2558717939 B2VFult2OverDischrgCurr 10000;
BA_ "GenSigTimeoutTime_BMU" SG_ 2558717939 B2VFult2OverChrgCurrInTheDrive 10000;
BA_ "GenSigTimeoutTime_BMU" SG_ 2558717939 B2VFult2CurrSensorErr 10000;
BA_ "GenSigTimeoutTime_BMU" SG_ 2558717939 B2VFult2PowerSupplyErr 10000;
BA_ "GenSigTimeoutTime_BMU" SG_ 2558717939 B2VFult2TMSErr 10000;
BA_ "GenSigTimeoutTime_BMU" SG_ 2558717939 B2VFult2HeatungFilmErr 10000;
BA_ "GenSigTimeoutTime_BMU" SG_ 2558717939 B2VFult2PackSelfProtect 10000;
BA_ "GenSigTimeoutTime_BMU" SG_ 2558717939 B2VFult2MainLoopPrechrgErr 10000;
BA_ "GenSigTimeoutTime_BMU" SG_ 2558717939 B2VFult2AuxLoopPrechrgErr 10000;
BA_ "GenSigTimeoutTime_BMU" SG_ 2558717939 B2VFult2ChrgInsLowErr 10000;
BA_ "GenSigTimeoutTime_BMU" SG_ 2558717939 B2VFult2ACANLost 10000;
BA_ "GenSigTimeoutTime_BMU" SG_ 2558717939 B2VFult2InnerCommunicationErr 10000;
BA_ "GenSigTimeoutTime_BMU" SG_ 2558717939 B2VFult2DCDCErr 10000;
BA_ "GenSigTimeoutTime_BMU" SG_ 2558717939 B2VFult2BranchBreakErr 10000;
BA_ "GenSigTimeoutTime_BMU" SG_ 2558717939 B2VFult2HeatRelayOpenErr 10000;
BA_ "GenSigTimeoutTime_BMU" SG_ 2558717939 B2VFult2HeatRelayWeldErr 10000;
BA_ "GenSigTimeoutTime_BMU" SG_ 2558717939 B2VFult2MainPosRelayOpenErr 10000;
BA_ "GenSigTimeoutTime_BMU" SG_ 2558717939 B2VFult2MainPosRelayWeldErr 10000;
BA_ "GenSigTimeoutTime_BMU" SG_ 2558717939 B2VFult2MainNegRelayOpenErr 10000;
BA_ "GenSigTimeoutTime_BMU" SG_ 2558717939 B2VFult2MainNegRelayWeldErr 10000;
BA_ "GenSigTimeoutTime_BMU" SG_ 2558717939 B2VFult2DCChrgPos1RelayOpenErr 10000;
BA_ "GenSigTimeoutTime_BMU" SG_ 2558717939 B2VFult2DCChrgPos1RelayWeldErr 10000;
BA_ "GenSigTimeoutTime_BMU" SG_ 2558717939 B2VFult2DCChrgNeg1RelayOpenErr 10000;
BA_ "GenSigTimeoutTime_BMU" SG_ 2558717939 B2VFult2DCChrgNeg1RelayWeldErr 10000;
BA_ "GenSigTimeoutTime_BMU" SG_ 2558717939 B2VFult2DCChrgPos2RelayOpenErr 10000;
BA_ "GenSigTimeoutTime_BMU" SG_ 2558717939 B2VFult2DCChrgPos2RelayWeldErr 10000;
BA_ "GenSigTimeoutTime_BMU" SG_ 2558717939 B2VFult2DCChrgNeg2RelayOpenErr 10000;
BA_ "GenSigTimeoutTime_BMU" SG_ 2558717939 B2VFult2DCChrgNeg2RelayWeldErr 10000;
BA_ "GenSigTimeoutTime_BMU" SG_ 2558717939 B2VFult2ACChrgPosRelayOpenErr 10000;
BA_ "GenSigTimeoutTime_BMU" SG_ 2558717939 B2VFult2ACChrgPosRelayWeldErr 10000;
BA_ "GenSigTimeoutTime_BMU" SG_ 2558717939 B2VFult2ACChrgNegRelayOpenErr 10000;
BA_ "GenSigTimeoutTime_BMU" SG_ 2558717939 B2VFult2ACChrgNegRelayWeldErr 10000;
BA_ "GenSigTimeoutTime_BMU" SG_ 2558717939 B2VFult2PantoChrgPosRelayOpenErr 10000;
BA_ "GenSigTimeoutTime_BMU" SG_ 2558717939 B2VFult2PantoChrgPosRelayWeldErr 10000;
BA_ "GenSigTimeoutTime_BMU" SG_ 2558717939 B2VFult2PantoChrgNegRelayOpenErr 10000;
BA_ "GenSigTimeoutTime_BMU" SG_ 2558717939 B2VFult2PantoChrgNegRelayWeldErr 10000;
BA_ "GenSigTimeoutTime_BMU" SG_ 2558717939 B2VFult2ChrgConnectErr 10000;
BA_ "GenSigTimeoutTime_BMU" SG_ 2558717939 B2VFlt2OverDschrgCrrWhnInChrg 10000;
BA_ "GenSigTimeoutTime_BMU" SG_ 2558717939 B2VFult2OverChrgCurrInTheChrg 10000;
BA_ "GenSigTimeoutTime_BMU" SG_ 2558717939 B2VFult2ChrgNTCErr 10000;
BA_ "GenSigTimeoutTime_BMU" SG_ 2558717939 B2VFult2ChrgNTCTempOver 10000;
BA_ "GenSigTimeoutTime_BMU" SG_ 2558717939 B2VFult2ELockErr 10000;
BA_ "GenSigTimeoutTime_BMU" SG_ 2558717939 B2VFult2FireDetectorErr 10000;
BA_ "GenSigTimeoutTime_BMU" SG_ 2558717939 B2VFult2ContiChrgCurrOverLoad 10000;
BA_ "GenSigTimeoutTime_BMU" SG_ 2558717939 B2VFult2SOCDifferErr 10000;
BA_ "GenSigTimeoutTime_BMU" SG_ 2558717939 B2VFult2ContiDischrgCurrOverLoad 10000;
BA_ "GenSigTimeoutTime_BMU" SG_ 2558717939 B2VFult2Reserved1 10000;
BA_ "GenSigTimeoutTime_BMU" SG_ 2558717939 B2VFult2Reserved2 10000;
BA_ "GenSigTimeoutTime_BMU" SG_ 2558783475 B2VST1MainPosRelaySt 10000;
BA_ "GenSigTimeoutTime_BMU" SG_ 2558783475 B2VST1MainNegRelaySt 10000;
BA_ "GenSigTimeoutTime_BMU" SG_ 2558783475 B2VST1PrechrgRelaySt 10000;
BA_ "GenSigTimeoutTime_BMU" SG_ 2558783475 B2VST1DCChrgPos1RelaySt 10000;
BA_ "GenSigTimeoutTime_BMU" SG_ 2558783475 B2VST1DCChrgNeg1RelaySt 10000;
BA_ "GenSigTimeoutTime_BMU" SG_ 2558783475 B2VST1DCChrgPos2RelaySt 10000;
BA_ "GenSigTimeoutTime_BMU" SG_ 2558783475 B2VST1DCChrgNeg2RelaySt 10000;
BA_ "GenSigTimeoutTime_BMU" SG_ 2558783475 B2VST1HeatPosRelaySt 10000;
BA_ "GenSigTimeoutTime_BMU" SG_ 2558783475 B2VST1HeatNegRelaySt 10000;
BA_ "GenSigTimeoutTime_BMU" SG_ 2558783475 B2VST1PantoChrgPosRelaySt 10000;
BA_ "GenSigTimeoutTime_BMU" SG_ 2558783475 B2VST1PantoChrgNegRelaySt 10000;
BA_ "GenSigTimeoutTime_BMU" SG_ 2558783475 B2VST1ACChrgPosRelaySt 10000;
BA_ "GenSigTimeoutTime_BMU" SG_ 2558783475 B2VST1ACChrgNegRelaySt 10000;
BA_ "GenSigTimeoutTime_BMU" SG_ 2558783475 B2VST1Aux1RelaySt 10000;
BA_ "GenSigTimeoutTime_BMU" SG_ 2558783475 B2VST1Aux2RelaySt 10000;
BA_ "GenSigTimeoutTime_BMU" SG_ 2558783475 B2VST1Aux3RelaySt 10000;
BA_ "GenSigTimeoutTime_BMU" SG_ 2558783475 B2VST1BMSHVStatus 10000;
BA_ "GenSigTimeoutTime_BMU" SG_ 2558783475 B2VST1BMSBalanceStatus 10000;
BA_ "GenSigTimeoutTime_BMU" SG_ 2558783475 B2VST1DCChrgConnectSt 10000;
BA_ "GenSigTimeoutTime_BMU" SG_ 2558783475 B2VST1PantoChrgConnectSt 10000;
BA_ "GenSigTimeoutTime_BMU" SG_ 2558783475 B2VST1ACChrgConnectSt 10000;
BA_ "GenSigTimeoutTime_BMU" SG_ 2558783475 B2VST1ChrgMode 10000;
BA_ "GenSigTimeoutTime_BMU" SG_ 2558783475 B2VST1ChrgStatus 10000;
BA_ "GenSigTimeoutTime_BMU" SG_ 2558783475 B2VST1HeatingStatus 10000;
BA_ "GenSigTimeoutTime_BMU" SG_ 2558783475 B2VST1CoolingStatus 10000;
BA_ "GenSigTimeoutTime_BMU" SG_ 2558783475 B2VST1RechrgCycels 10000;
BA_ "GenSigTimeoutTime_BMU" SG_ 2558849011 B2VST2SOC 10000;
BA_ "GenSigTimeoutTime_BMU" SG_ 2558849011 B2VST2SOH 10000;
BA_ "GenSigTimeoutTime_BMU" SG_ 2558849011 B2VST2PackCurrent 10000;
BA_ "GenSigStartValue" SG_ 2558849011 B2VST2PackCurrent 10000;
BA_ "GenSigTimeoutTime_BMU" SG_ 2558849011 B2VST2PackInsideVolt 10000;
BA_ "GenSigTimeoutTime_BMU" SG_ 2558849011 B2VST2FaultCode 10000;
BA_ "GenSigTimeoutTime_BMU" SG_ 2558849011 B2VST2FaultLevel 10000;
BA_ "GenSigTimeoutTime_BMU" SG_ 2558849011 B2VST2RqHVPoerOff 10000;
BA_ "GenSigTimeoutTime_BMU" SG_ 2558849011 B2VST2Life 10000;
BA_ "GenSigTimeoutTime_BMU" SG_ 2558914547 B2VST3PosInsRes 10000;
BA_ "GenSigTimeoutTime_BMU" SG_ 2558914547 B2VST3NegInsRes 10000;
BA_ "GenSigTimeoutTime_BMU" SG_ 2558914547 B2VST3SysInsRes 10000;
BA_ "GenSigTimeoutTime_BMU" SG_ 2558914547 B2VST3InsDetectorSt 10000;
BA_ "GenSigTimeoutTime_BMU" SG_ 2558914547 B2VST3Reserved1 10000;
BA_ "GenSigTimeoutTime_BMU" SG_ 2558980083 B2VST4MaxTemp 10000;
BA_ "GenSigStartValue" SG_ 2558980083 B2VST4MaxTemp 40;
BA_ "GenSigTimeoutTime_BMU" SG_ 2558980083 B2VST4MinTemp 10000;
BA_ "GenSigStartValue" SG_ 2558980083 B2VST4MinTemp 40;
BA_ "GenSigTimeoutTime_BMU" SG_ 2558980083 B2VST4AvgTemp 10000;
BA_ "GenSigStartValue" SG_ 2558980083 B2VST4AvgTemp 40;
BA_ "GenSigTimeoutTime_BMU" SG_ 2558980083 B2VST4MaxTempCSCNo 10000;
BA_ "GenSigStartValue" SG_ 2558980083 B2VST4MaxTempCSCNo 1;
BA_ "GenSigTimeoutTime_BMU" SG_ 2558980083 B2VST4MaxTempPosition 10000;
BA_ "GenSigStartValue" SG_ 2558980083 B2VST4MaxTempPosition 1;
BA_ "GenSigTimeoutTime_BMU" SG_ 2558980083 B2VST4MinTempCSCNo 10000;
BA_ "GenSigStartValue" SG_ 2558980083 B2VST4MinTempCSCNo 1;
BA_ "GenSigTimeoutTime_BMU" SG_ 2558980083 B2VST4MinTempPosition 10000;
BA_ "GenSigStartValue" SG_ 2558980083 B2VST4MinTempPosition 1;
BA_ "GenSigTimeoutTime_BMU" SG_ 2558980083 B2VST4Reserved1 10000;
BA_ "GenSigStartValue" SG_ 2558980083 B2VST4Reserved1 1;
BA_ "GenSigTimeoutTime_BMU" SG_ 2559045619 B2VST5MaxUcell 10000;
BA_ "GenSigTimeoutTime_BMU" SG_ 2559045619 B2VST5MinUcell 10000;
BA_ "GenSigTimeoutTime_BMU" SG_ 2559045619 B2VST5AvgUcell 10000;
BA_ "GenSigTimeoutTime_BMU" SG_ 2559045619 B2VST5Reserved1 10000;
BA_ "GenSigTimeoutTime_BMU" SG_ 2559111155 B2VST6MaxUcellCSCNo 10000;
BA_ "GenSigTimeoutTime_BMU" SG_ 2559111155 B2VST6MaxUcellPosition 10000;
BA_ "GenSigTimeoutTime_BMU" SG_ 2559111155 B2VST6MinUcellCSCNo 10000;
BA_ "GenSigTimeoutTime_BMU" SG_ 2559111155 B2VST6MinUcellPosition 10000;
BA_ "GenSigTimeoutTime_BMU" SG_ 2559111155 B2VST6Reserved1 10000;
BA_ "GenSigTimeoutTime_BMU" SG_ 2559176691 B2VST7Gun1DCPosTemp 10000;
BA_ "GenSigStartValue" SG_ 2559176691 B2VST7Gun1DCPosTemp 40;
BA_ "GenSigTimeoutTime_BMU" SG_ 2559176691 B2VST7Gun1DCNegTemp 10000;
BA_ "GenSigStartValue" SG_ 2559176691 B2VST7Gun1DCNegTemp 40;
BA_ "GenSigTimeoutTime_BMU" SG_ 2559176691 B2VST7Gun2DCPosTemp 10000;
BA_ "GenSigStartValue" SG_ 2559176691 B2VST7Gun2DCPosTemp 40;
BA_ "GenSigTimeoutTime_BMU" SG_ 2559176691 B2VST7Gun2DCNegTemp 10000;
BA_ "GenSigStartValue" SG_ 2559176691 B2VST7Gun2DCNegTemp 40;
BA_ "GenSigTimeoutTime_BMU" SG_ 2559176691 B2VST7GunACPosTemp 10000;
BA_ "GenSigStartValue" SG_ 2559176691 B2VST7GunACPosTemp 40;
BA_ "GenSigTimeoutTime_BMU" SG_ 2559176691 B2VST7GunACNegTemp 10000;
BA_ "GenSigStartValue" SG_ 2559176691 B2VST7GunACNegTemp 40;
BA_ "GenSigTimeoutTime_BMU" SG_ 2559176691 B2VST7Reserved1 10000;
BA_ "GenSigTimeoutTime_BMU" SG_ 2559176691 B2VST7Reserved2 10000;
BA_ "GenSigTimeoutTime_BMU" SG_ 2562977779 B2VTotChgEnergy 10000;
BA_ "GenSigTimeoutTime_BMU" SG_ 2562977779 B2VTotDischgEnergy 10000;
BA_ "GenSigTimeoutTime_BMU" SG_ 2562977779 B2VSingleChgEnergy 10000;
BA_ "GenSigTimeoutTime_BMU" SG_ 2563043315 B2VAvailInpulseDischrgCurr 10000;
BA_ "GenSigTimeoutTime_BMU" SG_ 2563043315 B2VAvailInpulseChrgCurr 10000;
BA_ "GenSigTimeoutTime_BMU" SG_ 2563043315 B2VAvailFollowChrgCurr 10000;
BA_ "GenSigTimeoutTime_BMU" SG_ 2563043315 B2VAvailFollowDishrgCurr 10000;
BA_ "GenSigTimeoutTime_BMU" SG_ 2563108851 B2VSVoltageSet 10000;
BA_ "GenSigTimeoutTime_BMU" SG_ 2563108851 B2VSCurrentSet 10000;
BA_ "GenSigTimeoutTime_BMU" SG_ 2563108851 B2VSChargeSta 10000;
BA_ "GenSigTimeoutTime_BMU" SG_ 2563108851 B2VChargeInfoReserved1 10000;
BA_ "GenSigTimeoutTime_BMU" SG_ 2550461423 V2BNVoltageOutput 10000;
BA_ "GenSigTimeoutTime_BMU" SG_ 2550461423 V2BNCurrentOutput 10000;
BA_ "GenSigTimeoutTime_BMU" SG_ 2550461423 V2BFChargerHardware 10000;
BA_ "GenSigTimeoutTime_BMU" SG_ 2550461423 V2BFChargerOverTemp 10000;
BA_ "GenSigTimeoutTime_BMU" SG_ 2550461423 V2BFChargerInputVoltage 10000;
BA_ "GenSigTimeoutTime_BMU" SG_ 2550461423 V2BStChargerReady 10000;
BA_ "GenSigTimeoutTime_BMU" SG_ 2550461423 V2BStChargerStart 10000;
BA_ "GenSigTimeoutTime_BMU" SG_ 2550461423 V2BFChargerCAN 10000;
BA_ "GenSigTimeoutTime_BMU" SG_ 2550461423 V2BStChargeAllow 10000;
BA_ "GenSigTimeoutTime_BMU" SG_ 2550461423 V2BStChargeMode 10000;
BA_ "GenSigTimeoutTime_BMU" SG_ 2550461423 V2BChargeStatusReserved1 10000;
BA_ "GenSigTimeoutTime_BMU" SG_ 2559242227 B2VChrgRelayCMD 10000;
BA_ "GenSigTimeoutTime_BMU" SG_ 2559242227 B2VHeatPosRelayCMD 10000;
BA_ "GenSigTimeoutTime_BMU" SG_ 2559242227 B2VHeatNegRelayCMD 10000;
BA_ "GenSigTimeoutTime_BMU" SG_ 2559242227 B2VMainPosRelayCMD 10000;
BA_ "GenSigTimeoutTime_BMU" SG_ 2559242227 B2VInsForbidCMD 10000;
BA_ "GenSigTimeoutTime_BMU" SG_ 2559242227 B2VMainNegRelayCoilSt 10000;
BA_ "GenSigTimeoutTime_BMU" SG_ 2559242227 B2VStatusOfRelayReserved1 10000;
BA_ "GenSigTimeoutTime_BMU" SG_ 2559242227 B2VStatusOfRelayReserved2 10000;
BA_ "GenSigTimeoutTime_BMU" SG_ 2566866420 B2TRQSetModeA 10000;
BA_ "GenSigTimeoutTime_BMU" SG_ 2566866420 B2TRQHVA 10000;
BA_ "GenSigTimeoutTime_BMU" SG_ 2566866420 B2TChgSTA 10000;
BA_ "GenSigTimeoutTime_BMU" SG_ 2566866420 B2TBMSHVRelaySTA 10000;
BA_ "GenSigTimeoutTime_BMU" SG_ 2566866420 B2TBMSHVVoltA 10000;
BA_ "GenSigTimeoutTime_BMU" SG_ 2566866420 B2TBMSR1 10000;
BA_ "GenSigTimeoutTime_BMU" SG_ 2566866420 B2TSetTempA 10000;
BA_ "GenSigStartValue" SG_ 2566866420 B2TSetTempA 40;
BA_ "GenSigTimeoutTime_BMU" SG_ 2566866420 B2TBMSR2 10000;
BA_ "GenSigTimeoutTime_BMU" SG_ 2566866420 B2TMBMSALIVA 10000;
BA_ "GenSigTimeoutTime_BMU" SG_ 2566866420 B2TMCRCA 10000;
BA_ "GenSigTimeoutTime_BMU" SG_ 2566897978 T2BWorkStatusA 10000;
BA_ "GenSigTimeoutTime_BMU" SG_ 2566897978 T2BTMSHVRelaySTA 10000;
BA_ "GenSigTimeoutTime_BMU" SG_ 2566897978 TM2BInfoReserved1 10000;
BA_ "GenSigTimeoutTime_BMU" SG_ 2566897978 TM2BOutletTempA 10000;
BA_ "GenSigStartValue" SG_ 2566897978 TM2BOutletTempA 40;
BA_ "GenSigTimeoutTime_BMU" SG_ 2566897978 TM2BInletTempA 10000;
BA_ "GenSigStartValue" SG_ 2566897978 TM2BInletTempA 40;
BA_ "GenSigTimeoutTime_BMU" SG_ 2566897978 TM2BInfoReserved2 10000;
BA_ "GenSigTimeoutTime_BMU" SG_ 2566897978 TM2BRQPowerA 10000;
BA_ "GenSigTimeoutTime_BMU" SG_ 2566897978 TM2BFaultCodeA 10000;
BA_ "GenSigTimeoutTime_BMU" SG_ 2566897978 TM2BFaultLevelA 10000;
BA_ "GenSigTimeoutTime_BMU" SG_ 2566911990 Fire2BBoxNo 10000;
BA_ "GenSigTimeoutTime_BMU" SG_ 2566911990 Fire2BBomType 10000;
BA_ "GenSigTimeoutTime_BMU" SG_ 2566911990 Fire2BFaultLevel 10000;
BA_ "GenSigTimeoutTime_BMU" SG_ 2566911990 Fire2BFaultCode 10000;
BA_ "GenSigTimeoutTime_BMU" SG_ 2566911990 Fire2BValveCmd 10000;
BA_ "GenSigTimeoutTime_BMU" SG_ 2566911990 Fire2BSysFaultCode 10000;
BA_ "GenSigTimeoutTime_BMU" SG_ 2566911990 Fire2BReserved2 10000;
BA_ "GenSigTimeoutTime_BMU" SG_ 2566911990 Fire2BRollingCounter 10000;
VAL_ 2550330351 V2BCMDLifeSignal 255 "Signal Invalid" ;
VAL_ 2550330351 V2BCMDHVOnOff 0 "Reserved" 1 "PowerOn" 2 "PowerOff" 3 " Invalid" ;
VAL_ 2550330351 V2BCMDAux1OnOff 0 "Reserved" 1 "PowerOn" 2 "PowerOff" 3 " Invalid" ;
VAL_ 2550330351 V2BCMDAux2OnOff 0 "Reserved" 1 "PowerOn" 2 "PowerOff" 3 " Invalid" ;
VAL_ 2550330351 V2BCMDAux3OnOff 0 "Reserved" 1 "PowerOn" 2 "PowerOff" 3 " Invalid" ;
VAL_ 2550330351 V2BCMDBatteryContactorPosST 0 "Reserved" 1 "Opened" 2 "Closed" 3 "Signal Invalid" ;
VAL_ 2550330351 V2BCMDBatteryContactorPosFlt 0 "Normal" 1 "Weld" 2 "Opened Fault" 3 "Signal Invalid" ;
VAL_ 2550330351 V2BCMDBatteryContactorNegST 0 "Reserved" 1 "Opened" 2 "Closed" 3 "Signal Invalid" ;
VAL_ 2550330351 V2BCMDBatteryContactorNegFlt 0 "Normal" 1 "Weld" 2 "Opened Fault" 3 "Signal Invalid" ;
VAL_ 2550330351 V2BCMDDCChargeContactorPosST 0 "Reserved" 1 "Opened" 2 "Closed" 3 "Signal Invalid" ;
VAL_ 2550330351 V2BCMDDCChargeContactorPosFlt 0 "Normal" 1 "Weld" 2 "Opened Fault" 3 "Signal Invalid" ;
VAL_ 2550330351 V2BCMDDCChargeContactorNegST 0 "Reserved" 1 "Opened" 2 "Closed" 3 "Signal Invalid" ;
VAL_ 2550330351 V2BCMDDCChargeContactorNegFlt 0 "Normal" 1 "Weld" 2 "Opened Fault" 3 "Signal Invalid" ;
VAL_ 2550330351 V2BCMDPantographContactorPosST 0 "Reserved" 1 "Opened" 2 "Closed" 3 "Signal Invalid" ;
VAL_ 2550330351 V2BCMDPantographContactorPosFlt 0 "Normal" 1 "Weld" 2 "Opened Fault" 3 "Signal Invalid" ;
VAL_ 2550330351 V2BCMDPantographContactorNegST 0 "Reserved" 1 "Opened" 2 "Closed" 3 "Signal Invalid" ;
VAL_ 2550330351 V2BCMDPantographContactorNegFlt 0 "Normal" 1 "Weld" 2 "Opened Fault" 3 "Signal Invalid" ;
VAL_ 2550330351 V2BCMDCharge1RelayST 0 "Reserved" 1 "Opened" 2 "Closed" 3 "Signal Invalid" ;
VAL_ 2550330351 V2BCMDCharge1RelayFlt 0 "Normal" 1 "Weld" 2 "Opened Fault" 3 "Signal Invalid" ;
VAL_ 2550330351 V2BCMDCharge2RelayST 0 "Reserved" 1 "Opened" 2 "Closed" 3 "Signal Invalid" ;
VAL_ 2550330351 V2BCMDCharge2RelayFlt 0 "Normal" 1 "Weld" 2 "Opened Fault" 3 "Signal Invalid" ;
VAL_ 2550330351 V2BCMDAux4RelayST 0 "Reserved" 1 "Opened" 2 "Closed" 3 "Signal Invalid" ;
VAL_ 2550330351 V2BCMDAux4RelayFlt 0 "Normal" 1 "Weld" 2 "Opened Fault" 3 "Signal Invalid" ;
VAL_ 2550395887 ISOWorkStatus 0 "Selfcheck" 1 "working" 2 "stop work" 3 "equipment failure" ;
VAL_ 2550395887 ISOFaultLevel 0 "Normal" 1 "Level 1-Light fault" 2 "Level 2-More severe fault" 3 "Level3-Most severe fault" ;
VAL_ 2550263795 B2VRQVIN 0 "Not Request VIN" 1 "Request VIN" ;
VAL_ 2564944879 V2BVINFrameNo 1 "Frame1" 2 "Frame2" 3 "Frame3" ;
VAL_ 2564944879 V2BVINB1815 48 "0" 49 "1" 50 "2" 51 "3" 52 "4" 53 "5" 54 "6" 55 "7" 56 "8" 57 "9" 65 "A" 66 "B" 67 "C" 68 "D" 69 "E" 70 "F" 71 "G" 72 "H" 73 "I" 74 "J" 75 "K" 76 "L" 77 "M" 78 "N" 79 "O" 80 "P" 81 "Q" 82 "R" 83 "S" 84 "T" 85 "U" 86 "V" 87 "W" 88 "X" 89 "Y" 90 "Z" ;
VAL_ 2564944879 V2BVINB2916 48 "0" 49 "1" 50 "2" 51 "3" 52 "4" 53 "5" 54 "6" 55 "7" 56 "8" 57 "9" 65 "A" 66 "B" 67 "C" 68 "D" 69 "E" 70 "F" 71 "G" 72 "H" 73 "I" 74 "J" 75 "K" 76 "L" 77 "M" 78 "N" 79 "O" 80 "P" 81 "Q" 82 "R" 83 "S" 84 "T" 85 "U" 86 "V" 87 "W" 88 "X" 89 "Y" 90 "Z" ;
VAL_ 2564944879 V2BVINB31017 48 "0" 49 "1" 50 "2" 51 "3" 52 "4" 53 "5" 54 "6" 55 "7" 56 "8" 57 "9" 65 "A" 66 "B" 67 "C" 68 "D" 69 "E" 70 "F" 71 "G" 72 "H" 73 "I" 74 "J" 75 "K" 76 "L" 77 "M" 78 "N" 79 "O" 80 "P" 81 "Q" 82 "R" 83 "S" 84 "T" 85 "U" 86 "V" 87 "W" 88 "X" 89 "Y" 90 "Z" ;
VAL_ 2564944879 V2BVINB411 48 "0" 49 "1" 50 "2" 51 "3" 52 "4" 53 "5" 54 "6" 55 "7" 56 "8" 57 "9" 65 "A" 66 "B" 67 "C" 68 "D" 69 "E" 70 "F" 71 "G" 72 "H" 73 "I" 74 "J" 75 "K" 76 "L" 77 "M" 78 "N" 79 "O" 80 "P" 81 "Q" 82 "R" 83 "S" 84 "T" 85 "U" 86 "V" 87 "W" 88 "X" 89 "Y" 90 "Z" ;
VAL_ 2564944879 V2BVINB512 48 "0" 49 "1" 50 "2" 51 "3" 52 "4" 53 "5" 54 "6" 55 "7" 56 "8" 57 "9" 65 "A" 66 "B" 67 "C" 68 "D" 69 "E" 70 "F" 71 "G" 72 "H" 73 "I" 74 "J" 75 "K" 76 "L" 77 "M" 78 "N" 79 "O" 80 "P" 81 "Q" 82 "R" 83 "S" 84 "T" 85 "U" 86 "V" 87 "W" 88 "X" 89 "Y" 90 "Z" ;
VAL_ 2564944879 V2BVINB613 48 "0" 49 "1" 50 "2" 51 "3" 52 "4" 53 "5" 54 "6" 55 "7" 56 "8" 57 "9" 65 "A" 66 "B" 67 "C" 68 "D" 69 "E" 70 "F" 71 "G" 72 "H" 73 "I" 74 "J" 75 "K" 76 "L" 77 "M" 78 "N" 79 "O" 80 "P" 81 "Q" 82 "R" 83 "S" 84 "T" 85 "U" 86 "V" 87 "W" 88 "X" 89 "Y" 90 "Z" ;
VAL_ 2564944879 V2BVINB714 48 "0" 49 "1" 50 "2" 51 "3" 52 "4" 53 "5" 54 "6" 55 "7" 56 "8" 57 "9" 65 "A" 66 "B" 67 "C" 68 "D" 69 "E" 70 "F" 71 "G" 72 "H" 73 "I" 74 "J" 75 "K" 76 "L" 77 "M" 78 "N" 79 "O" 80 "P" 81 "Q" 82 "R" 83 "S" 84 "T" 85 "U" 86 "V" 87 "W" 88 "X" 89 "Y" 90 "Z" ;
VAL_ 2564943859 B2VSNFrameNo 1 "Frame1" 2 "Frame2" 3 "Frame3" 4 "Frame4" ;
VAL_ 2564943859 B2VSNSysCodeB171319 48 "0" 49 "1" 50 "2" 51 "3" 52 "4" 53 "5" 54 "6" 55 "7" 56 "8" 57 "9" 65 "A" 66 "B" 67 "C" 68 "D" 69 "E" 70 "F" 71 "G" 72 "H" 73 "I" 74 "J" 75 "K" 76 "L" 77 "M" 78 "N" 79 "O" 80 "P" 81 "Q" 82 "R" 83 "S" 84 "T" 85 "U" 86 "V" 87 "W" 88 "X" 89 "Y" 90 "Z" ;
VAL_ 2564943859 B2VSNSysCodeB281420 48 "0" 49 "1" 50 "2" 51 "3" 52 "4" 53 "5" 54 "6" 55 "7" 56 "8" 57 "9" 65 "A" 66 "B" 67 "C" 68 "D" 69 "E" 70 "F" 71 "G" 72 "H" 73 "I" 74 "J" 75 "K" 76 "L" 77 "M" 78 "N" 79 "O" 80 "P" 81 "Q" 82 "R" 83 "S" 84 "T" 85 "U" 86 "V" 87 "W" 88 "X" 89 "Y" 90 "Z" ;
VAL_ 2564943859 B2VSNSysCodeB391521 48 "0" 49 "1" 50 "2" 51 "3" 52 "4" 53 "5" 54 "6" 55 "7" 56 "8" 57 "9" 65 "A" 66 "B" 67 "C" 68 "D" 69 "E" 70 "F" 71 "G" 72 "H" 73 "I" 74 "J" 75 "K" 76 "L" 77 "M" 78 "N" 79 "O" 80 "P" 81 "Q" 82 "R" 83 "S" 84 "T" 85 "U" 86 "V" 87 "W" 88 "X" 89 "Y" 90 "Z" ;
VAL_ 2564943859 B2VSNSysCodeB4101622 48 "0" 49 "1" 50 "2" 51 "3" 52 "4" 53 "5" 54 "6" 55 "7" 56 "8" 57 "9" 65 "A" 66 "B" 67 "C" 68 "D" 69 "E" 70 "F" 71 "G" 72 "H" 73 "I" 74 "J" 75 "K" 76 "L" 77 "M" 78 "N" 79 "O" 80 "P" 81 "Q" 82 "R" 83 "S" 84 "T" 85 "U" 86 "V" 87 "W" 88 "X" 89 "Y" 90 "Z" ;
VAL_ 2564943859 B2VSNSysCodeB5111723 48 "0" 49 "1" 50 "2" 51 "3" 52 "4" 53 "5" 54 "6" 55 "7" 56 "8" 57 "9" 65 "A" 66 "B" 67 "C" 68 "D" 69 "E" 70 "F" 71 "G" 72 "H" 73 "I" 74 "J" 75 "K" 76 "L" 77 "M" 78 "N" 79 "O" 80 "P" 81 "Q" 82 "R" 83 "S" 84 "T" 85 "U" 86 "V" 87 "W" 88 "X" 89 "Y" 90 "Z" ;
VAL_ 2564943859 B2VSNSysCodeB6121824 48 "0" 49 "1" 50 "2" 51 "3" 52 "4" 53 "5" 54 "6" 55 "7" 56 "8" 57 "9" 65 "A" 66 "B" 67 "C" 68 "D" 69 "E" 70 "F" 71 "G" 72 "H" 73 "I" 74 "J" 75 "K" 76 "L" 77 "M" 78 "N" 79 "O" 80 "P" 81 "Q" 82 "R" 83 "S" 84 "T" 85 "U" 86 "V" 87 "W" 88 "X" 89 "Y" 90 "Z" ;
VAL_ 2565009395 B2VBI1RateCap 65535 "Signal Invalid" ;
VAL_ 2565009395 B2VBI1RateHVolt 65535 "Signal Invalid" ;
VAL_ 2565009395 B2VBI1RatePower 65535 "Signal Invalid" ;
VAL_ 2565009395 B2VBI1BattType 1 "铅酸电池Lead-acid battery" 2 "镍氢电池NI-MH Battery" 3 "磷酸铁锂电池LEP" 4 "锰酸锂电池" 5 "钴酸锂电池" 6 "三元材料电池 NCM" 7 "聚合物锂离子电池 Polymer li-ion battery" 8 "钛酸锂电池" 9 "超级电容Super-capaciyor" 10 "Reserved" 11 "Reserved" 12 "Reserved" 13 "Reserved" 14 "燃料电池 Fuel battery" 15 "其他车载储能装置" ;
VAL_ 2565009395 B2VBI1CoolType 0 "Other cooling mode" 1 "Natural cooling" 2 "Fan cooling" 3 "Water cooling" ;
VAL_ 2565009395 B2VBI1BattManufacture 1 "CATL" 2 "Li Shen" 3 "MGL" 4 "SAMSUN" 5 "LG" 6 "GUOXUAN HIGH_TECH" 7 "SUNWODA" 8 "Others" ;
VAL_ 2565074931 B2VBI2TotCSCNum 255 "Signal Invalid" ;
VAL_ 2565074931 B2VBI2PackTotCellNum 65535 "Invalid" ;
VAL_ 2565074931 B2VBI2PackTotTempNum 255 "Signal Invalid" ;
VAL_ 2565074931 B2VBI2HVBranchNum 255 "Signal Invalid" ;
VAL_ 2565074931 B2VBI2SingleHVBranchCellNum 255 "Signal Invalid" ;
VAL_ 2565074931 B2VBI2BattSysNum 255 "Signal Invalid" ;
VAL_ 2565074931 B2VBI2BattSysSeqNum 255 "Signal Invalid" ;
VAL_ 2565140467 B2VBI3PackAvaiMaxVolt 65535 "Invalid" ;
VAL_ 2565140467 B2VBI3PackAvaiMinVolt 65535 "Invalid" ;
VAL_ 2565140467 B2VBI3AvaiMaxSOC 255 "Invalid" ;
VAL_ 2565140467 B2VBI3AvaiMinSOC 255 "Invalid" ;
VAL_ 2565140467 B2VBI3AvaiMaxTemp 255 "Invalid" ;
VAL_ 2565140467 B2VBI3AvaiMinTemp 255 "Invalid" ;
VAL_ 2562846707 B2VVFrameNo 65535 "Invalid" ;
VAL_ 2562846707 B2VVCellVoltN1 65535 "Invalid" ;
VAL_ 2562846707 B2VVCellVoltN2 65535 "Invalid" ;
VAL_ 2562846707 B2VVCellVoltN3 65535 "Invalid" ;
VAL_ 2562912243 B2VTFrameNo 65535 "Invalid" ;
VAL_ 2562912243 B2VTCellTempN1 255 "Invalid" ;
VAL_ 2562912243 B2VTCellTempN2 255 "Invalid" ;
VAL_ 2562912243 B2VTCellTempN3 255 "Invalid" ;
VAL_ 2562912243 B2VTCellTempN4 255 "Invalid" ;
VAL_ 2562912243 B2VTCellTempN5 255 "Invalid" ;
VAL_ 2562912243 B2VTCellTempN6 255 "Invalid" ;
VAL_ 2558652403 B2VFult1DelTemp 0 "Normal" 1 "Level 1-Light fault" 2 "Level 2-More severe fault" 3 "Level3-Most severe fault" ;
VAL_ 2558652403 B2VFult1OverTemp 0 "Normal" 1 "Level 1-Light fault" 2 "Level 2-More severe fault" 3 "Level3-Most severe fault" ;
VAL_ 2558652403 B2VFult1PackOverHVolt 0 "Normal" 1 "Level 1-Light fault" 2 "Level 2-More severe fault" 3 "Level3-Most severe fault" ;
VAL_ 2558652403 B2VFult1PackLowHVolt 0 "Normal" 1 "Level 1-Light fault" 2 "Level 2-More severe fault" 3 "Level3-Most severe fault" ;
VAL_ 2558652403 B2VFult1LowSOC 0 "Normal" 1 "Level 1-Light fault" 2 "Level 2-More severe fault" 3 "Level3-Most severe fault" ;
VAL_ 2558652403 B2VFult1OverUcell 0 "Normal" 1 "Level 1-Light fault" 2 "Level 2-More severe fault" 3 "Level3-Most severe fault" ;
VAL_ 2558652403 B2VFult1LowUcell 0 "Normal" 1 "Level 1-Light fault" 2 "Level 2-More severe fault" 3 "Level3-Most severe fault" ;
VAL_ 2558652403 B2VFult1LowInsRes 0 "Normal" 1 "Level 1-Light fault" 2 "Level 2-More severe fault" 3 "Level3-Most severe fault" ;
VAL_ 2558652403 B2VFult1UcellUniformity 0 "Normal" 1 "Level 1-Light fault" 2 "Level 2-More severe fault" 3 "Level3-Most severe fault" ;
VAL_ 2558652403 B2VFult1OverChg 0 "Normal" 1 "Level 1-Light fault" 2 "Level 2-More severe fault" 3 "Level3-Most severe fault" ;
VAL_ 2558652403 B2VFult1OverSOC 0 "Normal" 1 "Level 1-Light fault" 2 "Level 2-More severe fault" 3 "Level3-Most severe fault" ;
VAL_ 2558652403 B2VFult1SOCChangeFast 0 "Normal" 1 "Fault" ;
VAL_ 2558652403 B2VFult1BatSysNotMatch 0 "Normal" 1 "Fault" ;
VAL_ 2558652403 B2VFult1HVILFault 0 "Normal" 1 "Fault" ;
VAL_ 2558717939 B2VFult2CellOverDischrg 0 "Normal" 1 "Fault" ;
VAL_ 2558717939 B2VFult2CellLowTemp 0 "Normal" 1 "Fault" ;
VAL_ 2558717939 B2VFult2PackFireWarning 0 "Normal" 1 "Fault" ;
VAL_ 2558717939 B2VFult2OverDischrgCurr 0 "Normal" 1 "Level 1-Light fault" 2 "Level 2-More severe fault" 3 "Level3-Most severe fault" ;
VAL_ 2558717939 B2VFult2OverChrgCurrInTheDrive 0 "Normal" 1 "Level 1-Light fault" 2 "Level 2-More severe fault" 3 "Level3-Most severe fault" ;
VAL_ 2558717939 B2VFult2CurrSensorErr 0 "Normal" 1 "Fault" ;
VAL_ 2558717939 B2VFult2PowerSupplyErr 0 "Normal" 1 "Fault" ;
VAL_ 2558717939 B2VFult2TMSErr 0 "Normal" 1 "Fault" ;
VAL_ 2558717939 B2VFult2HeatungFilmErr 0 "Normal" 1 "Fault" ;
VAL_ 2558717939 B2VFult2PackSelfProtect 0 "Normal" 1 "Fault" ;
VAL_ 2558717939 B2VFult2MainLoopPrechrgErr 0 "Normal" 1 "Fault" ;
VAL_ 2558717939 B2VFult2AuxLoopPrechrgErr 0 "Normal" 1 "Fault" ;
VAL_ 2558717939 B2VFult2ChrgInsLowErr 0 "Normal" 1 "Fault" ;
VAL_ 2558717939 B2VFult2ACANLost 0 "Normal" 1 "Fault" ;
VAL_ 2558717939 B2VFult2InnerCommunicationErr 0 "Normal" 1 "Fault" ;
VAL_ 2558717939 B2VFult2DCDCErr 0 "Normal" 1 "Fault" ;
VAL_ 2558717939 B2VFult2BranchBreakErr 0 "Normal" 1 "Fault" ;
VAL_ 2558717939 B2VFult2HeatRelayOpenErr 0 "Normal" 1 "Fault" ;
VAL_ 2558717939 B2VFult2HeatRelayWeldErr 0 "Normal" 1 "Fault" ;
VAL_ 2558717939 B2VFult2MainPosRelayOpenErr 0 "Normal" 1 "Fault" ;
VAL_ 2558717939 B2VFult2MainPosRelayWeldErr 0 "Normal" 1 "Fault" ;
VAL_ 2558717939 B2VFult2MainNegRelayOpenErr 0 "Normal" 1 "Fault" ;
VAL_ 2558717939 B2VFult2MainNegRelayWeldErr 0 "Normal" 1 "Fault" ;
VAL_ 2558717939 B2VFult2DCChrgPos1RelayOpenErr 0 "Normal" 1 "Fault" ;
VAL_ 2558717939 B2VFult2DCChrgPos1RelayWeldErr 0 "Normal" 1 "Fault" ;
VAL_ 2558717939 B2VFult2DCChrgNeg1RelayOpenErr 0 "Normal" 1 "Fault" ;
VAL_ 2558717939 B2VFult2DCChrgNeg1RelayWeldErr 0 "Normal" 1 "Fault" ;
VAL_ 2558717939 B2VFult2DCChrgPos2RelayOpenErr 0 "Normal" 1 "Fault" ;
VAL_ 2558717939 B2VFult2DCChrgPos2RelayWeldErr 0 "Normal" 1 "Fault" ;
VAL_ 2558717939 B2VFult2DCChrgNeg2RelayOpenErr 0 "Normal" 1 "Fault" ;
VAL_ 2558717939 B2VFult2DCChrgNeg2RelayWeldErr 0 "Normal" 1 "Fault" ;
VAL_ 2558717939 B2VFult2ACChrgPosRelayOpenErr 0 "Normal" 1 "Fault" ;
VAL_ 2558717939 B2VFult2ACChrgPosRelayWeldErr 0 "Normal" 1 "Fault" ;
VAL_ 2558717939 B2VFult2ACChrgNegRelayOpenErr 0 "Normal" 1 "Fault" ;
VAL_ 2558717939 B2VFult2ACChrgNegRelayWeldErr 0 "Normal" 1 "Fault" ;
VAL_ 2558717939 B2VFult2PantoChrgPosRelayOpenErr 0 "Normal" 1 "Fault" ;
VAL_ 2558717939 B2VFult2PantoChrgPosRelayWeldErr 0 "Normal" 1 "Fault" ;
VAL_ 2558717939 B2VFult2PantoChrgNegRelayOpenErr 0 "Normal" 1 "Fault" ;
VAL_ 2558717939 B2VFult2PantoChrgNegRelayWeldErr 0 "Normal" 1 "Fault" ;
VAL_ 2558717939 B2VFult2ChrgConnectErr 0 "Normal" 1 "Fault" ;
VAL_ 2558717939 B2VFlt2OverDschrgCrrWhnInChrg 0 "Normal" 1 "Fault" ;
VAL_ 2558717939 B2VFult2OverChrgCurrInTheChrg 0 "Normal" 1 "Fault" ;
VAL_ 2558717939 B2VFult2ChrgNTCErr 0 "Normal" 1 "Fault" ;
VAL_ 2558717939 B2VFult2ChrgNTCTempOver 0 "Normal" 1 "Level 1-Light fault" 2 "Level 2-More severe fault" 3 "Level3-Most severe fault" ;
VAL_ 2558717939 B2VFult2ELockErr 0 "Normal" 1 "Fault" ;
VAL_ 2558717939 B2VFult2FireDetectorErr 0 "Normal" 1 "Fault" ;
VAL_ 2558717939 B2VFult2ContiChrgCurrOverLoad 0 "Normal" 1 "Level 1-Light fault" 2 "Level 2-More severe fault" 3 "Level3-Most severe fault" ;
VAL_ 2558717939 B2VFult2SOCDifferErr 0 "Normal" 1 "Fault" ;
VAL_ 2558717939 B2VFult2ContiDischrgCurrOverLoad 0 "Normal" 1 "Level 1-Light fault" 2 "Level 2-More severe fault" 3 "Level3-Most severe fault" ;
VAL_ 2558783475 B2VST1MainPosRelaySt 0 "Reserved" 1 "Open" 2 "Closed" 3 "Signal Invalid" ;
VAL_ 2558783475 B2VST1MainNegRelaySt 0 "Reserved" 1 "Open" 2 "Closed" 3 "Signal Invalid" ;
VAL_ 2558783475 B2VST1PrechrgRelaySt 0 "Reserved" 1 "Open" 2 "Closed" 3 "Signal Invalid" ;
VAL_ 2558783475 B2VST1DCChrgPos1RelaySt 0 "Reserved" 1 "Open" 2 "Closed" 3 "Signal Invalid" ;
VAL_ 2558783475 B2VST1DCChrgNeg1RelaySt 0 "Reserved" 1 "Open" 2 "Closed" 3 "Signal Invalid" ;
VAL_ 2558783475 B2VST1DCChrgPos2RelaySt 0 "Reserved" 1 "Open" 2 "Closed" 3 "Signal Invalid" ;
VAL_ 2558783475 B2VST1DCChrgNeg2RelaySt 0 "Reserved" 1 "Open" 2 "Closed" 3 "Signal Invalid" ;
VAL_ 2558783475 B2VST1HeatPosRelaySt 0 "Reserved" 1 "Open" 2 "Closed" 3 "Signal Invalid" ;
VAL_ 2558783475 B2VST1HeatNegRelaySt 0 "Reserved" 1 "Open" 2 "Closed" 3 "Signal Invalid" ;
VAL_ 2558783475 B2VST1PantoChrgPosRelaySt 0 "Reserved" 1 "Open" 2 "Closed" 3 "Signal Invalid" ;
VAL_ 2558783475 B2VST1PantoChrgNegRelaySt 0 "Reserved" 1 "Open" 2 "Closed" 3 "Signal Invalid" ;
VAL_ 2558783475 B2VST1ACChrgPosRelaySt 0 "Reserved" 1 "Open" 2 "Closed" 3 "Signal Invalid" ;
VAL_ 2558783475 B2VST1ACChrgNegRelaySt 0 "Reserved" 1 "Open" 2 "Closed" 3 "Signal Invalid" ;
VAL_ 2558783475 B2VST1Aux1RelaySt 0 "Reserved" 1 "Open" 2 "Closed" 3 "Signal Invalid" ;
VAL_ 2558783475 B2VST1Aux2RelaySt 0 "Reserved" 1 "Open" 2 "Closed" 3 "Signal Invalid" ;
VAL_ 2558783475 B2VST1Aux3RelaySt 0 "Reserved" 1 "Open" 2 "Closed" 3 "Signal Invalid" ;
VAL_ 2558783475 B2VST1BMSHVStatus 0 "HV open" 1 "Precharge or Precheck" 2 "HV closed" 3 "Fail to HV on" ;
VAL_ 2558783475 B2VST1BMSBalanceStatus 0 "No Balancing" 1 "Balancing" ;
VAL_ 2558783475 B2VST1DCChrgConnectSt 0 "Not connected" 1 "single gun connect" 2 "double gun connect" 3 "Invalid" ;
VAL_ 2558783475 B2VST1PantoChrgConnectSt 0 "Not connected" 1 "Connected" ;
VAL_ 2558783475 B2VST1ACChrgConnectSt 0 "Not connected" 1 "Connected" ;
VAL_ 2558783475 B2VST1ChrgMode 0 "Notcharging" 1 "DC charging" 2 "AC charging" 3 "Other charging" ;
VAL_ 2558783475 B2VST1ChrgStatus 0 "not charging" 1 "Charging" 2 "Charge Finished" 3 "Charge error" ;
VAL_ 2558783475 B2VST1HeatingStatus 0 "not heat" 1 "heating" ;
VAL_ 2558783475 B2VST1CoolingStatus 0 "not cooling " 1 "cooling" ;
VAL_ 2558849011 B2VST2SOC 255 "Signal Invalid" ;
VAL_ 2558849011 B2VST2SOH 255 "Signal Invalid" ;
VAL_ 2558849011 B2VST2PackCurrent 65535 "Signal Invalid" ;
VAL_ 2558849011 B2VST2PackInsideVolt 65535 "Signal Invalid" ;
VAL_ 2558849011 B2VST2FaultCode 255 "Signal Invalid" ;
VAL_ 2558849011 B2VST2FaultLevel 0 "Normal" 1 "Level 1-Light fault" 2 "Level 2-More severe fault" 3 "Level3-Most severe fault" ;
VAL_ 2558849011 B2VST2RqHVPoerOff 0 "not require power off" 1 "require power off" ;
VAL_ 2558849011 B2VST2Life 15 "Signal Invalid" ;
VAL_ 2558914547 B2VST3PosInsRes 65535 "Signal Invalid" ;
VAL_ 2558914547 B2VST3NegInsRes 65535 "Signal Invalid" ;
VAL_ 2558914547 B2VST3SysInsRes 65535 "Signal Invalid" ;
VAL_ 2558914547 B2VST3InsDetectorSt 0 "stop insulation detection " 1 "insulation detection active " ;
VAL_ 2558914547 B2VST3Reserved1 65535 "Signal Invalid" ;
VAL_ 2558980083 B2VST4MaxTemp 254 "Abnormal" 255 "Signal Invalid" ;
VAL_ 2558980083 B2VST4MinTemp 254 "Abnormal" 255 "Signal Invalid" ;
VAL_ 2558980083 B2VST4AvgTemp 254 "Abnormal" 255 "Signal Invalid" ;
VAL_ 2558980083 B2VST4MaxTempCSCNo 1 "CSC1" 2 "CSC2" 3 "CSC3" 4 "CSC4" 5 "CSC5" 6 "CSC6" 7 "CSC7" 8 "CSC8" 9 "CSC9" 10 "CSC10" 11 "CSC11" 12 "CSC12" 13 "CSC13" 14 "CSC14" 15 "CSC15" 16 "CSC16" 17 "CSC17" 18 "CSC18" 255 "Signal Invalid" ;
VAL_ 2558980083 B2VST4MinTempCSCNo 1 "CSC1" 2 "CSC2" 3 "CSC3" 4 "CSC4" 5 "CSC5" 6 "CSC6" 7 "CSC7" 8 "CSC8" 9 "CSC9" 10 "CSC10" 11 "CSC11" 12 "CSC12" 13 "CSC13" 14 "CSC14" 15 "CSC15" 16 "CSC16" 17 "CSC17" 18 "CSC18" 255 "Signal Invalid" ;
VAL_ 2559045619 B2VST5MaxUcell 65535 "Signal Invalid" ;
VAL_ 2559045619 B2VST5MinUcell 65535 "Signal Invalid" ;
VAL_ 2559045619 B2VST5AvgUcell 65535 "Signal Invalid" ;
VAL_ 2559045619 B2VST5Reserved1 65535 "Signal Invalid" ;
VAL_ 2559111155 B2VST6MaxUcellCSCNo 1 "CSC1" 2 "CSC2" 3 "CSC3" 4 "CSC4" 5 "CSC5" 6 "CSC6" 7 "CSC7" 8 "CSC8" 9 "CSC9" 10 "CSC10" 11 "CSC11" 12 "CSC12" 13 "CSC13" 14 "CSC14" 15 "CSC15" 16 "CSC16" 17 "CSC17" 18 "CSC18" 255 "Signal Invalid" ;
VAL_ 2559111155 B2VST6MinUcellCSCNo 1 "CSC1" 2 "CSC2" 3 "CSC3" 4 "CSC4" 5 "CSC5" 6 "CSC6" 7 "CSC7" 8 "CSC8" 9 "CSC9" 10 "CSC10" 11 "CSC11" 12 "CSC12" 13 "CSC13" 14 "CSC14" 15 "CSC15" 16 "CSC16" 17 "CSC17" 18 "CSC18" 255 "Signal Invalid" ;
VAL_ 2559176691 B2VST7Gun1DCPosTemp 255 "Signal Invalid" ;
VAL_ 2559176691 B2VST7Gun1DCNegTemp 255 "Signal Invalid" ;
VAL_ 2559176691 B2VST7Gun2DCPosTemp 255 "Signal Invalid" ;
VAL_ 2559176691 B2VST7Gun2DCNegTemp 255 "Signal Invalid" ;
VAL_ 2559176691 B2VST7GunACPosTemp 255 "Signal Invalid" ;
VAL_ 2559176691 B2VST7GunACNegTemp 255 "Signal Invalid" ;
VAL_ 2559176691 B2VST7Reserved1 255 "Signal Invalid" ;
VAL_ 2559176691 B2VST7Reserved2 255 "Signal Invalid" ;
VAL_ 2563108851 B2VSChargeSta 0 "Start to charge" 1 "Normal Stop to charge" 2 "Fault, Stop to charge" ;
VAL_ 2550461423 V2BFChargerHardware 0 "OK" 1 "Fault" ;
VAL_ 2550461423 V2BFChargerOverTemp 0 "OK" 1 "Fault" ;
VAL_ 2550461423 V2BFChargerInputVoltage 0 "OK" 1 "Fault" ;
VAL_ 2550461423 V2BStChargerReady 0 "Normal" 1 "Fault(overtime)" ;
VAL_ 2550461423 V2BStChargerStart 0 "On" 1 "Off(in order to prevent Battery reverse connection)" ;
VAL_ 2550461423 V2BFChargerCAN 0 "Normal" 1 "Fault(overtime)" ;
VAL_ 2550461423 V2BStChargeAllow 0 "Not Charging" 1 "Allow Charging" 2 "Stop Charging" 3 " Invalid" ;
VAL_ 2550461423 V2BStChargeMode 0 "Notcharging" 1 "DC charging" 2 "AC charging" 3 "Other charging" ;
VAL_ 2559242227 B2VChrgRelayCMD 0 "require contactor open" 1 "require contactor close" 2 "Reserved" 3 "Reserved" ;
VAL_ 2559242227 B2VHeatPosRelayCMD 0 "require contactor open" 1 "require contactor close" 2 "Reserved" 3 "Reserved" ;
VAL_ 2559242227 B2VHeatNegRelayCMD 0 "require contactor open" 1 "require contactor close" 2 "Reserved" 3 "Reserved" ;
VAL_ 2559242227 B2VMainPosRelayCMD 0 "require contactor open" 1 "require contactor close" 2 "Reserved" 3 "Reserved" ;
VAL_ 2559242227 B2VInsForbidCMD 0 "forbid insulation detection" 1 "allow insulation detection" 2 "Reserved" 3 "Reserved" ;
VAL_ 2559242227 B2VMainNegRelayCoilSt 0 "coil opened" 1 "coil closed" 2 "Reserved" 3 "Reserved" ;
VAL_ 2566866420 B2TRQSetModeA 0 "Shutdown Mode" 1 "Cooling Mode" 2 "Heat Mode" 3 "Self-Loop Mode" ;
VAL_ 2566866420 B2TRQHVA 0 "HV On Request" 1 "HV Off Request" 2 "Invalid" 3 "Invalid" ;
VAL_ 2566866420 B2TChgSTA 0 "Non-Charging mode" 1 " Charging mode" 2 "Invalid" 3 "Invalid" ;
VAL_ 2566866420 B2TBMSHVRelaySTA 0 "Open" 1 "Closed" 2 "Invalid" 3 "Invalid" ;
VAL_ 2566866420 B2TBMSHVVoltA 65535 "Invalid" ;
VAL_ 2566897978 T2BWorkStatusA 0 "Shutdown Mode" 1 "Cooling Mode" 2 "Heat Mode" 3 "Self-Loop Mode" ;
VAL_ 2566897978 T2BTMSHVRelaySTA 0 "Open" 1 "Close" ;
VAL_ 2566897978 TM2BOutletTempA 255 "Invalid" ;
VAL_ 2566897978 TM2BInletTempA 255 "Invalid" ;
VAL_ 2566897978 TM2BRQPowerA 65535 "Invalid" ;
VAL_ 2566897978 TM2BFaultCodeA 0 "No fault" 1 "Bus under voltage,Level 1 Fault" 2 "Bus over voltage,Level 1 Fault" 3 "Over current,Level 2 Fault" 4 "Inner Communication abnormal,Level 1 Fault" 5 "Lost speed,Level 2 Fault" 6 "Abnormal,Level 2 Fault" 7 "System pressure protect,Level 2 Fault" 8 "Prevent freezing protect,Level 2 Fault" 9 "Outlet temperature sensor abnormal,Level 2 Fault" 10 "Inlet temperature sensor abnormal,Level 2 Fault" 11 "Prevent freezing temperature sensor abnormal,Level 2 Fault" 12 "Water pump fault,Level 1 Fault" 13 "PTC Fault, Level 1 Fault" 14 "CAN communication abnormal,Level 1 Fault" 15 "Vent temperature protect,Level 2 Fault" 16 "Vent temperature sensor abnormal,Level 2 Fault" 17 "Environment temperature sensor abnormal,Level 2 Fault" ;
VAL_ 2566897978 TM2BFaultLevelA 1 "Level 1 Fault" 2 "Level 2 Fault" 3 "Level 3 Fault" ;
VAL_ 2566911990 Fire2BBomType 0 "保留" 1 "保留" 2 "自动：火情4级，上级设备控制启动" 3 "自动：火情4级，探测器自动检测启动" 4 "手动：强制控制，上级设备启动" 5 "手动：强制控制，探测器自检测启动" 6 "探测器失控启动" 7 "其他启动" 255 "探测器无灭火器或子阀门控制时，在虚拟控制灭火弹，告知上级设备应备份数据" ;
VAL_ 2566911990 Fire2BFaultLevel 0 "Normal" 1 "Level 1 Fault" 2 "Level 2 Fault" 3 "Level 3 Fault" 4 "Level 4 Fault" ;
VAL_ 2566911990 Fire2BFaultCode 0 "正常" 1 "灭火器已启动" 2 "传感器故障" 3 "硬件故障" ;
VAL_ 2566911990 Fire2BValveCmd 1 "子阀打开" 2 "子阀关闭" 3 "子阀等待开启" ;
